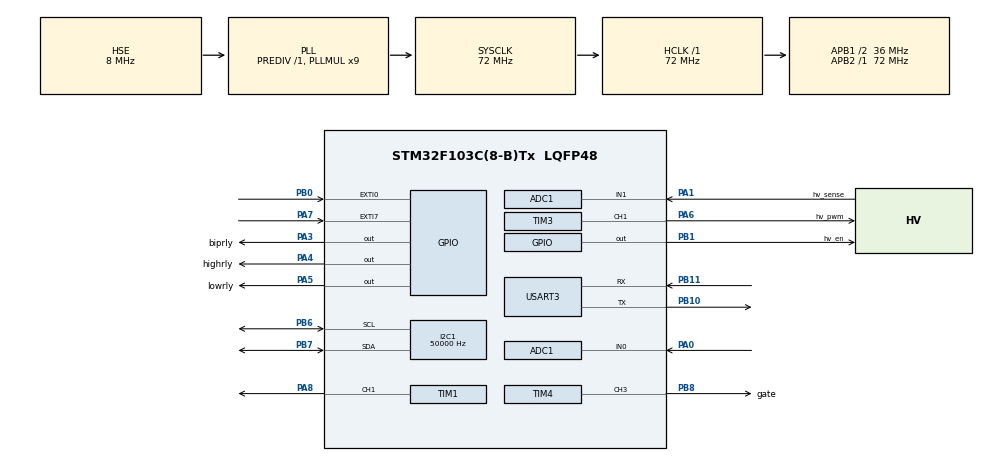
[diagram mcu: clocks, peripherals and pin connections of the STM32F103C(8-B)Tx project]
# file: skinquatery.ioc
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ADC1.Channel-3\#ChannelRegularConversion=ADC_CHANNEL_1
ADC1.Channel-4\#ChannelRegularConversion=ADC_CHANNEL_0
ADC1.ContinuousConvMode=ENABLE
ADC1.NbrOfConversion=2
ADC1.NbrOfConversionFlag=1
ADC1.Rank-3\#ChannelRegularConversion=1
ADC1.Rank-4\#ChannelRegularConversion=2
ADC1.SamplingTime-3\#ChannelRegularConversion=ADC_SAMPLETIME_28CYCLES_5
ADC1.SamplingTime-4\#ChannelRegularConversion=ADC_SAMPLETIME_28CYCLES_5
ADC1.master=1
Dma.ADC1.0.Direction=DMA_PERIPH_TO_MEMORY
Dma.ADC1.0.Instance=DMA1_Channel1
Dma.ADC1.0.MemDataAlignment=DMA_MDATAALIGN_HALFWORD
Dma.ADC1.0.MemInc=DMA_MINC_ENABLE
Dma.ADC1.0.Mode=DMA_CIRCULAR
Dma.ADC1.0.PeriphDataAlignment=DMA_PDATAALIGN_HALFWORD
Dma.ADC1.0.PeriphInc=DMA_PINC_DISABLE
Dma.ADC1.0.Priority=DMA_PRIORITY_LOW
Dma.Request0=ADC1
I2C1.ClockSpeed=50000
Mcu.Family=STM32F1
Mcu.Name=STM32F103C(8-B)Tx
Mcu.Package=LQFP48
NVIC.DMA1_Channel1_IRQn=true\:0\:0\:false\:false\:true\:false\:true\:true
NVIC.EXTI0_IRQn=true\:0\:0\:false\:false\:true\:true\:true\:true
NVIC.EXTI9_5_IRQn=true\:0\:0\:false\:false\:true\:true\:true\:true
NVIC.PriorityGroup=NVIC_PRIORITYGROUP_4
NVIC.USART3_IRQn=true\:0\:0\:false\:false\:true\:true\:true\:true
PA0-WKUP.Signal=ADCx_IN0
PA1.GPIO_Label=hv_sense
PA1.Signal=ADCx_IN1
PA13.Mode=Serial_Wire
PA13.Signal=SYS_JTMS-SWDIO
PA14.Mode=Serial_Wire
PA14.Signal=SYS_JTCK-SWCLK
PA3.GPIO_Label=biprly
PA3.Signal=GPIO_Output
PA4.GPIO_Label=highrly
PA4.Signal=GPIO_Output
PA5.GPIO_Label=lowrly
PA5.Signal=GPIO_Output
PA6.GPIO_Label=hv_pwm
PA6.Signal=S_TIM3_CH1
PA7.GPIO_ModeDefaultEXTI=GPIO_MODE_IT_RISING_FALLING
PA7.Signal=GPXTI7
PA8.Signal=S_TIM1_CH1
PB0.GPIO_ModeDefaultEXTI=GPIO_MODE_IT_RISING_FALLING
PB0.Signal=GPXTI0
PB1.GPIO_Label=hv_en
PB1.Signal=GPIO_Output
PB10.Mode=Asynchronous
PB10.Signal=USART3_TX
PB11.Mode=Asynchronous
PB11.Signal=USART3_RX
PB6.Mode=I2C
PB6.Signal=I2C1_SCL
PB7.Mode=I2C
PB7.Signal=I2C1_SDA
PB8.GPIO_Label=gate
PB8.Signal=S_TIM4_CH3
PD0-OSC_IN.Mode=HSE-External-Oscillator
PD0-OSC_IN.Signal=RCC_OSC_IN
PD1-OSC_OUT.Mode=HSE-External-Oscillator
PD1-OSC_OUT.Signal=RCC_OSC_OUT
ProjectManager.HeapSize=0x200
ProjectManager.StackSize=0x400
ProjectManager.TargetToolchain=STM32CubeIDE
RCC.ADCPresc=RCC_ADCPCLK2_DIV6
RCC.AHBFreq_Value=72000000
RCC.APB1CLKDivider=RCC_HCLK_DIV2
RCC.APB1Freq_Value=36000000
RCC.APB1TimFreq_Value=72000000
RCC.APB2Freq_Value=72000000
RCC.APB2TimFreq_Value=72000000
RCC.HCLKFreq_Value=72000000
RCC.PLLMUL=RCC_PLL_MUL9
RCC.PLLSourceVirtual=RCC_PLLSOURCE_HSE
RCC.SYSCLKFreq_VALUE=72000000
RCC.SYSCLKSource=RCC_SYSCLKSOURCE_PLLCLK
RCC.USBFreq_Value=72000000
SH.ADCx_IN0.0=ADC1_IN0,IN0
SH.ADCx_IN1.0=ADC1_IN1,IN1
SH.S_TIM1_CH1.0=TIM1_CH1,PWM Generation1 CH1
SH.S_TIM3_CH1.0=TIM3_CH1,PWM Generation1 CH1
SH.S_TIM4_CH3.0=TIM4_CH3,PWM Generation3 CH3
TIM1.Channel-PWM\ Generation1\ CH1=TIM_CHANNEL_1
TIM1.Period=999
TIM1.Prescaler=44
TIM3.AutoReloadPreload=TIM_AUTORELOAD_PRELOAD_ENABLE
TIM3.Channel-PWM\ Generation1\ CH1=TIM_CHANNEL_1
TIM3.Period=999
TIM3.Prescaler=2
TIM3.Pulse-PWM\ Generation1\ CH1=0
TIM4.AutoReloadPreload=TIM_AUTORELOAD_PRELOAD_ENABLE
TIM4.Channel-PWM\ Generation3\ CH3=TIM_CHANNEL_3
TIM4.Period=2999
TIM4.Pulse-PWM\ Generation3\ CH3=1500
USART3.VirtualMode=VM_ASYNC
board=custom

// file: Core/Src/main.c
/* USER CODE BEGIN Header */
/**
 ******************************************************************************
 * @file           : main.c
 * @brief          : Main program body
 ******************************************************************************
 * @attention
 *
 * Copyright (c) 2025 STMicroelectronics.
 * All rights reserved.
 *
 * This software is licensed under terms that can be found in the LICENSE file
 * in the root directory of this software component.
 * If no LICENSE file comes with this software, it is provided AS-IS.
 *
 ******************************************************************************
 */
/* USER CODE END Header */
#include "main.h"

/* USER CODE BEGIN Includes */
#include <stdbool.h>
#include <string.h>   // For memset()

/* USER CODE END Includes */

/* USER CODE BEGIN PD */
#define TIM3_ARR 2999
#define INPUT_MIN_HIBI  0x00
#define INPUT_MAX_HIBI 0x23
#define INPUT_MIN_LOW  0x00
#define INPUT_MAX_LOW  0xc8
#define DEBOUNCE_MS 20
#define HIGH_THRESHOLD_CH0 1.7f
#define LOW_THRESHOLD_CH0  0.0f
#define HIGH_THRESHOLD_CH1 3.2f
#define LOW_THRESHOLD_CH1  0.0f

#define ADC_MAX_VALUE   4095.0f
#define VDDA_VOLTAGE    3.3f
#define VP_LOW_VALUE         0x1000  // DWIN variable address for low value
#define VP_LOW_DATA          0x3002  // DWIN variable address for low numeric display
#define VP_VAR_ICON          0x2000  // DWIN variable address for variable icon
#define VP_MODE              0x3000  // DWIN variable address for mode (was wrongly 0x2000)
#define VP_MODE_DATA         0x3003  // DWIN page-1 value (high/bipolar only)
#define EEPROM_ADDR_MODE     0x000A  // EEPROM storage for mode (0x4d/0x4e/0x4f)
#define EEPROM_MODE_MAGIC    0xA5
#define EEPROM_ADDR_HIGH     0x0014  // EEPROM storage for high value (separate)
#define EEPROM_ADDR_BIPOLAR  0x0018  // EEPROM storage for bipolar value (separate)
#define EEPROM_ADDR_LOW      0x002A  // EEPROM storage for VP 0x1000 low value
#define EEPROM_ADDR_PAGE     0x002E  // EEPROM storage for last DWIN page (1 or 2)
#define EEPROM_PAGE_MAGIC    0xA5    // Valid page record marker byte
#define EEPROM_ADDR_PAGE_OLD 0x0200  // Legacy page address (migration read)
#define EEPROM_ADDR_VAR_ICON 0x0030  // EEPROM storage for VP 0x2000 var icon
#define EEPROM_ADDR_VAR_ICON_OLD 0x0300  // Legacy icon address (migration read)
#define EEPROM_ICON_MAGIC    0xA5    // Valid icon record marker byte
#define LOW_VALUE_MAX        200     // Maximum low value (INPUT_MAX_LOW)
#define BOOT_VAR_ICON_VALUE  78      // Default icon (low mode)
#define MIN_VAR_ICON_VALUE   77      // Bipolar icon
#define VAR_ICON_KEY_MAX     79      // High icon
#define ICON_BIPOLAR         77      // Return key 0x004D
#define ICON_LOW             78      // Return key 0x004E
#define ICON_HIGH            79      // Return key 0x004F
#define MODE_KEY_HIGH        0x004F  // VP 0x2000 return key — high mode
#define MODE_KEY_LOW         0x004E  // VP 0x2000 return key — low mode
#define MODE_KEY_BIPOLAR     0x004D  // VP 0x2000 return key — bipolar mode
#define DEFAULT_BRIGHTNESS   100     // Boot default if EEPROM empty (0-100)
#define MIN_BRIGHTNESS       30      // VP 0x0082 minimum — never go below this
#define VP_BRIGHTNESS        0x0082  // DWIN backlight variable
#define PAGE_BIPOLAR_RUN     4U      // Footswitch page — VP 0x3003 bipolar
#define PAGE_HIGH_RUN        5U      // Footswitch page — VP 0x3003 high
#define PAGE_LOW_RUN         6U      // Footswitch page — VP 0x3002 low
#define PAGE_HIBI_SET        1U      // Settings page — high / bipolar
#define PAGE_LOW_SET         2U      // Settings page — low
/* USER CODE END PD */

ADC_HandleTypeDef hadc1;
DMA_HandleTypeDef hdma_adc1;

I2C_HandleTypeDef hi2c1;

TIM_HandleTypeDef htim1;
TIM_HandleTypeDef htim3;
TIM_HandleTypeDef htim4;

UART_HandleTypeDef huart3;

/* USER CODE BEGIN PV */
#define DWIN_PKT_MAX         20
#define DWIN_RX_Q_DEPTH      8

int count;
int test;
uint8_t RxData[DWIN_PKT_MAX];
uint8_t rxBuffer[12];
uint8_t rxData[DWIN_PKT_MAX];
volatile uint16_t rxIndex = 0;
static uint8_t uart_rx_started = 0;
static volatile uint32_t last_rx_tick = 0;   /* set on every received byte */

typedef struct {
    uint8_t len;
    uint8_t data[DWIN_PKT_MAX];
} dwin_rx_pkt_t;

static volatile dwin_rx_pkt_t dwin_rx_q[DWIN_RX_Q_DEPTH];
static volatile uint8_t dwin_q_w = 0;
static volatile uint8_t dwin_q_r = 0;
uint16_t address, dataa, mode, high, bipolar, low, icon_id, brightnes,
		current_page, previous_mode;
uint8_t duty;
bool number_eeprome_flag = false;
bool sett_pg_chg = false;
bool eeprom_err = false;
uint32_t err = 0;
bool ch_pg_flag = false;
uint8_t TxData[8] = { 0x5A, 0xA5, 0x05, 0x82, 0x50, 0x02, 0x00, 0x0a };
uint8_t data[2], modee[2], highh[2], bipolarr[2], loww[2], vp3003w[2], icon_array[2],
		brightness[2], current_page_array[2];
uint16_t vp3003_val = 0;
uint16_t prev_address;
uint16_t prev_dataa;
uint16_t previous_low = 0;
uint16_t previous_high = 0;
uint16_t previous_bipolar = 0;
volatile uint8_t dwin_pkt_ready = 0;
static uint32_t low_save_enable_tick = 0;
static uint32_t low_display_push_until = 0;
static uint32_t var_icon_display_push_until = 0;
static uint32_t var_icon_boot_push_until = 0;
static uint32_t var_icon_aggressive_until = 0;
static uint32_t var_icon_save_enable_tick = 0;
static uint32_t brightness_display_push_until = 0;
static uint32_t brightness_save_enable_tick = 0;
static uint8_t brightness_user_touched = 0;
static uint8_t low_user_touched = 0;
static uint32_t low_last_accept_tick = 0;
static uint32_t low_eeprom_save_deadline = 0;
static uint8_t low_eeprom_dirty = 0;
static uint8_t low_display_pending = 0;
static uint32_t high_eeprom_save_deadline = 0;
static uint8_t high_eeprom_dirty = 0;
static uint32_t bipolar_eeprom_save_deadline = 0;
static uint8_t bipolar_eeprom_dirty = 0;
static uint8_t vp3003_display_pending = 0;
static uint32_t low_hold_last_rx_ms = 0;
static uint8_t low_hold_stream = 0;
static uint32_t low_hold_step_ms = 0;
static uint32_t low_vp1000_refresh_until = 0;
static uint16_t low_last_tx_word = 0xFFFF;
#define LOW_UART_QUIET_MS    1000U
#define LOW_RX_RAW_MAX       0x0999U  /* allow BCD 12.0 = 0x0120 from DWIN */

/* ===== TEMP DIAGNOSTIC =====
 * When set to 1, every VP 0x1000 value the DWIN sends is echoed *raw* (no
 * conversion) onto VP 0x3002. This lets us read on-screen exactly what the
 * DWIN transmits for a given key press. Set back to 0 once captured. */
#define LOW_DIAG_RAW   0

/* VP 0x1000 is the low increment on page 2 (and can appear on run pages). */
static uint8_t dwin_page_is_low(void) {
    return (current_page == PAGE_HIBI_SET || current_page == PAGE_LOW_SET ||
            current_page == PAGE_BIPOLAR_RUN || current_page == PAGE_LOW_RUN);
}

static uint8_t dwin_tx_low_quiet(void) {
    if (mode != 0x4e || !low_user_touched) {
        return 0U;
    }
    if (!dwin_page_is_low()) {
        return 0U;
    }
    return ((HAL_GetTick() - low_last_accept_tick) < LOW_UART_QUIET_MS) ? 1U : 0U;
}

static uint32_t vp3003_last_accept_tick = 0;
#define VP3003_UART_QUIET_MS  800U

static uint8_t dwin_tx_page1_quiet(void) {
    if (current_page != 1U) {
        return 0U;
    }
    if (mode != 0x4f && mode != 0x4d) {
        return 0U;
    }
    if (vp3003_last_accept_tick == 0U) {
        return 0U;
    }
    return ((HAL_GetTick() - vp3003_last_accept_tick) < VP3003_UART_QUIET_MS) ? 1U : 0U;
}

static uint8_t dwin_tx_user_adjust_quiet(void) {
    return (dwin_tx_low_quiet() || dwin_tx_page1_quiet()) ? 1U : 0U;
}
static uint32_t vp3003_save_enable_tick = 0;
static uint32_t vp3003_page1_restore_until = 0;
static uint8_t vp3003_user_touched = 0;
static uint32_t vp3003_rx_ignore_until = 0;
static uint32_t boot_rx_lock_until = 0;
static uint8_t saved_settings_page = 0;
static uint8_t var_icon_user_locked = 0;
static uint32_t boot_page_guard_until = 0;
uint32_t delta = 0;
float frequency = 0.0;
volatile uint8_t footswitch = 0;
volatile uint8_t active = 0;
volatile uint32_t pa7_last_irq = 0;
volatile uint8_t pa7_pending = 0;
volatile uint32_t pb0_last_irq = 0;
volatile uint8_t pb0_pending = 0;
uint8_t pagechange[10] = { 0x5A, 0xA5, 0x07, 0x82, 0x00, 0x84, 0x5A, 0x01, 0x00, 0x01 };
uint8_t mapped_duty = 0;

uint16_t adc_dma_buf[2];
uint16_t adc_raw_ch1;
uint16_t adc_raw_ch0;
uint32_t last_adc_tick = 0;
uint8_t alert_hv = 0;
uint8_t alert_gate = 0;

float ch1_voltage;
float ch0_voltage=1.6f;

// Variable icon storage (VP 0x2000)
uint16_t var_icon_value = BOOT_VAR_ICON_VALUE;
uint8_t var_icon_data[2] = {0x00, 0x4E};  // 78 = 0x004E low icon
/* USER CODE END PV */

void SystemClock_Config(void);
static void MX_GPIO_Init(void);
static void MX_DMA_Init(void);
static void MX_ADC1_Init(void);
static void MX_TIM3_Init(void);
static void MX_TIM4_Init(void);
static void MX_I2C1_Init(void);
static void MX_USART3_UART_Init(void);
static void MX_TIM1_Init(void);
/* USER CODE BEGIN PFP */
void bi_hi_pwm(uint16_t dataa);
void lowfunction(uint16_t dataa);
void TIM3_SetDutyPercent(uint8_t duty);
void save_reading(void);
void send_loadings(void);
void debouncing(void);
void hv_adc_reading(void);
void send_low_to_display(void);
void send_page_change(uint8_t page_num);
void dwin_boot_to_page(uint8_t page_num);
void dwin_uart_rx_start(void);
void low_value_user_changed(uint16_t new_low, uint16_t src_addr);
void send_variable_data(uint8_t addr_high, uint8_t addr_low, uint8_t data_high, uint8_t data_low);
void dwin_set_var_icon(uint16_t icon_id);
void send_var_icon_to_display(void);
void dwin_apply_boot_var_icon(void);
void eeprom_read_low_value(void);
void eeprom_save_low_value(void);
void eeprom_read_brightness(void);
void dwin_send_brightness(void);
void dwin_refresh_brightness(void);
void low_sync_both_vps(void);
void low_push_display_from_eeprom(void);
void eeprom_read_vp3003_value(void);
void eeprom_read_var_icon(void);
void eeprom_save_var_icon(void);
void eeprom_save_current_page(uint8_t page_num);
static void dwin_restore_page_from_eeprom(uint8_t page_num);
static void dwin_show_settings_page(uint8_t page_num);
static void dwin_arm_page2_restore_timers(void);
static void dwin_arm_var_icon_timers(void);
static void dwin_restore_var_icon_from_eeprom(uint8_t burst_count);
static void dwin_push_icon_from_eeprom(void);
static void dwin_icon_burst_from_eeprom(uint8_t count);
static uint8_t var_icon_from_mode_key(uint16_t key);
static uint8_t var_icon_from_mode(uint16_t m);
static void var_icon_apply_return_key(uint16_t key);
static uint8_t dwin_get_boot_page(void);
void dwin_restore_saved_state(uint8_t page_num);
void vp3003_send_to_display(void);
static void vp3003_send_to_display_force(void);
static void vp3003_push_display_burst(uint8_t count);
static void vp3003_bind_active(void);
static void vp3003_hold_service(void);
static void eeprom_save_hibi_slot(uint16_t which_mode);
static void hibi_persist_now(uint16_t which_mode);
static void eeprom_read_hibi_slot(uint16_t which_mode);
static void eeprom_save_mode_now(void);
static void eeprom_persist_all_values(void);
static void eeprom_persist_leaving_state(uint16_t old_mode);
static void dwin_picset_force(uint8_t page_num);
static void dwin_after_page_values(uint8_t page_num);
static uint16_t mode_normalize(uint16_t raw);
void vp3003_user_changed(uint16_t new_val);
void dwin_refresh_page2_values(void);
void dwin_open_page2(void);
void dwin_refresh_page1_values(void);
void dwin_open_page1(void);
/* USER CODE END PFP */

/* USER CODE BEGIN 0 */
static uint8_t i2c_eeprom_read16(uint16_t addr, uint8_t *buf);
static void dwin_uart_send(const uint8_t *data, uint16_t len);
static void send_var_icon_fast(void);
static void dwin_icon_burst_fast(uint8_t count);
static void send_variable_data_fast(uint8_t ah, uint8_t al, uint8_t dh, uint8_t dl);
static void low_apply_value(uint16_t val);
static void low_push_vps_fast(void);
static void low_burst_vp3002(uint8_t n);
static void low_persist_now(void);
static void low_hold_service(void);
static void low_vp1000_rx(uint16_t rx_val);

/* VP 0x1000 is a DGUS Variable Icon: the value it holds is an ICON INDEX.
 *   icon 0..99    -> 0.0 .. 9.9   (tenths = icon)
 *   icon 100..110 -> 10   .. 20   (tenths = (icon - 90) * 10)
 * Internally `low` is kept in tenths (0..200). VP 0x3002 is a 1-decimal
 * numeric box, so it takes tenths directly. */
static uint16_t low_icon_to_tenths(uint16_t icon) {
    if (icon <= 99U) {
        return icon;
    }
    if (icon <= 110U) {
        return (uint16_t)((icon - 90U) * 10U);
    }
    return LOW_VALUE_MAX;   /* 200 = 20.0 */
}

static uint16_t low_tenths_to_icon(uint16_t tenths) {
    if (tenths > LOW_VALUE_MAX) {
        tenths = LOW_VALUE_MAX;
    }
    if (tenths <= 99U) {
        return tenths;                       /* 0.0-9.9 -> icon 0-99 */
    }
    return (uint16_t)((tenths / 10U) + 90U); /* 10.0-20.0 -> icon 100-110 */
}

static uint16_t low_rx_to_tenths(uint16_t val) {
    return low_icon_to_tenths(val);
}

static uint16_t low_display_word(void) {
    uint16_t v = (previous_low != 0U && low == 0U) ? previous_low : low;
    if (v > LOW_VALUE_MAX) {
        v = LOW_VALUE_MAX;
    }
    return v;
}

static void low_push_vp3002_only(void) {
    /* VP 0x3002 is a 1-decimal Data Variable display: send the value in tenths
     * (e.g. 18.0 -> 180). VP 0x1000 (Variable Icon) gets the icon index instead. */
    uint16_t tenths = low_display_word();
    uint8_t d2h = (uint8_t)((tenths >> 8) & 0xFF);
    uint8_t d2l = (uint8_t)(tenths & 0xFF);
    uint8_t cmd[8] = {0x5A, 0xA5, 0x05, 0x82,
                      (uint8_t)((VP_LOW_DATA >> 8) & 0xFF),
                      (uint8_t)(VP_LOW_DATA & 0xFF), d2h, d2l};
    dwin_uart_send(cmd, 8);
    low_last_tx_word = tenths;
}

/* VP 0x1000: only rewrite 0.0–9.9. For 10–20 leave DWIN's value (writing tenths blanks it). */
static void low_push_vp1000_only(void) {
    uint16_t tenths;
    uint16_t icon;
    uint8_t cmd[8];
    if (dwin_tx_low_quiet()) {
        return;
    }
    tenths = low_display_word();
    icon = low_tenths_to_icon(tenths);   /* VP 0x1000 is a Variable Icon: send icon index */
    cmd[0] = 0x5A; cmd[1] = 0xA5; cmd[2] = 0x05; cmd[3] = 0x82;
    cmd[4] = (uint8_t)((VP_LOW_VALUE >> 8) & 0xFF);
    cmd[5] = (uint8_t)(VP_LOW_VALUE & 0xFF);
    cmd[6] = (uint8_t)((icon >> 8) & 0xFF);
    cmd[7] = (uint8_t)(icon & 0xFF);
    dwin_uart_send(cmd, 8);
    low_last_tx_word = tenths;
}

static void low_arm_page2_vp1000(void) {
    low_vp1000_refresh_until = HAL_GetTick() + 4000U;
}

static void low_burst_vp3002(uint8_t n) {
    uint8_t i;
    for (i = 0U; i < n; i++) {
        low_push_vp3002_only();
        HAL_Delay(8);
    }
}

/* After PICSET, paint the same low word on VP 0x1000 and VP 0x3002. */
static void low_burst_vp1000(uint8_t n) {
    uint8_t i;
    for (i = 0U; i < n; i++) {
        low_push_vp1000_only();
        low_push_vp3002_only();
        HAL_Delay(8);
    }
    low_arm_page2_vp1000();
}

static uint16_t mode_normalize(uint16_t raw) {
    if (raw == 0x4dU || raw == 0x4eU || raw == 0x4fU) {
        return raw;
    }
    raw &= 0x00FFU;
    if (raw == 0x4dU || raw == 0x4eU || raw == 0x4fU) {
        return raw;
    }
    return 0U;
}

static uint16_t mode_from_icon(uint16_t icon) {
    if (icon == ICON_HIGH) {
        return 0x4fU;
    }
    if (icon == ICON_LOW) {
        return 0x4eU;
    }
    if (icon == ICON_BIPOLAR) {
        return 0x4dU;
    }
    return 0U;
}

static uint16_t hibi_clamp(uint16_t raw) {
    if (raw == 0xFFFFU) {
        return 0U;
    }
    if (raw > INPUT_MAX_HIBI) {
        return INPUT_MAX_HIBI;
    }
    return raw;
}

static void dwin_picset_force(uint8_t page_num) {
    uint8_t cmd[10] = {
        0x5A, 0xA5, 0x07, 0x82, 0x00, 0x84,
        0x5A, 0x01, 0x00, page_num
    };
    dwin_uart_send(cmd, 10);
    current_page = page_num;
}

static void dwin_rx_queue_push(const uint8_t *pkt, uint8_t len) {
    uint8_t next = (uint8_t)((dwin_q_w + 1U) % DWIN_RX_Q_DEPTH);
    if (next == dwin_q_r) {
        dwin_q_r = (uint8_t)((dwin_q_r + 1U) % DWIN_RX_Q_DEPTH);
    }
    if (len > DWIN_PKT_MAX) {
        len = DWIN_PKT_MAX;
    }
    memcpy((void *)dwin_rx_q[dwin_q_w].data, pkt, len);
    dwin_rx_q[dwin_q_w].len = len;
    dwin_q_w = next;
}

static uint8_t dwin_rx_queue_pop(uint8_t *pkt, uint8_t max_len) {
    if (dwin_q_r == dwin_q_w) {
        return 0U;
    }
    uint8_t len = dwin_rx_q[dwin_q_r].len;
    if (len > max_len) {
        len = max_len;
    }
    memcpy(pkt, (const void *)dwin_rx_q[dwin_q_r].data, len);
    dwin_q_r = (uint8_t)((dwin_q_r + 1U) % DWIN_RX_Q_DEPTH);
    return len;
}

static void dwin_rx_collect_packets(void) {
    while (rxIndex >= 5U) {
        if (rxData[0] != 0x5A || rxData[1] != 0xA5) {
            memmove(rxData, rxData + 1, rxIndex - 1U);
            rxIndex--;
            continue;
        }
        uint8_t total_len = (uint8_t)(rxData[2] + 3U);
        if (total_len < 4U || total_len > DWIN_PKT_MAX) {
            memmove(rxData, rxData + 1, rxIndex - 1U);
            rxIndex--;
            continue;
        }
        if (rxIndex < total_len) {
            break;
        }
        dwin_rx_queue_push(rxData, total_len);
        if (rxIndex > total_len) {
            memmove(rxData, rxData + total_len, rxIndex - total_len);
            rxIndex = (uint16_t)(rxIndex - total_len);
        } else {
            rxIndex = 0;
        }
    }
}

void HAL_UART_RxCpltCallback(UART_HandleTypeDef *huart) {
	if (huart->Instance == USART3) {
		last_rx_tick = HAL_GetTick();
		if (rxIndex < sizeof(rxData)) {
			rxData[rxIndex++] = rxBuffer[0];
		}

		HAL_UART_Receive_IT(&huart3, rxBuffer, 1);
		dwin_rx_collect_packets();
	}
}

void HAL_GPIO_EXTI_Callback(uint16_t GPIO_Pin) {
	if (GPIO_Pin == GPIO_PIN_7) {
		pa7_last_irq = HAL_GetTick();
		pa7_pending = 1;
	}

	if (GPIO_Pin == GPIO_PIN_0) {
		pb0_last_irq = HAL_GetTick();
		pb0_pending = 1;
	}
}

void dwin_uart_rx_start(void) {
    if (!uart_rx_started) {
        rxIndex = 0;
        memset(rxData, 0, sizeof(rxData));
        HAL_UART_Receive_IT(&huart3, rxBuffer, 1);
        uart_rx_started = 1;
        boot_rx_lock_until = HAL_GetTick() + 3000U;
    }
}

void dwin_rx_get_vp(uint16_t *addr, uint16_t *data, uint8_t *valid) {
    *valid = 0;
    if (RxData[0] != 0x5A || RxData[1] != 0xA5 || RxData[2] < 3) {
        return;
    }

    *addr = (uint16_t)(((uint16_t)RxData[4] << 8) | RxData[5]);
    uint16_t max_val = LOW_VALUE_MAX;
    if (*addr == VP_MODE_DATA) {
        if (mode == 0x4f || mode == 0x4d) {
            max_val = INPUT_MAX_HIBI;
        }
    } else if (*addr == VP_VAR_ICON) {
        max_val = VAR_ICON_KEY_MAX;
    } else if (*addr == VP_BRIGHTNESS) {
        max_val = 100;
    }

    uint8_t cmd = RxData[3];
    uint8_t len = RxData[2];

    /* Return keys 0x004D / 0x004E / 0x004F must parse even if byte order varies. */
    if (*addr == VP_VAR_ICON) {
        uint16_t cand[4] = {0, 0, 0, 0};
        uint8_t n = 0U;
        if (cmd == 0x83 && len >= 6) {
            cand[n++] = (uint16_t)(((uint16_t)RxData[7] << 8) | RxData[8]);
            cand[n++] = (uint16_t)(((uint16_t)RxData[8] << 8) | RxData[7]);
        }
        if (len >= 5) {
            cand[n++] = (uint16_t)(((uint16_t)RxData[6] << 8) | RxData[7]);
            cand[n++] = (uint16_t)(((uint16_t)RxData[7] << 8) | RxData[6]);
        }
        {
            uint8_t i;
            for (i = 0U; i < n; i++) {
                uint16_t v = cand[i];
                if (v == 0x004DU || v == 0x004EU || v == 0x004FU ||
                    v == 0x4dU || v == 0x4eU || v == 0x4fU) {
                    *data = v;
                    *valid = 1;
                    return;
                }
            }
        }
    }

    if (*addr == VP_BRIGHTNESS && cmd == 0x83) {
        if (len >= 6) {
            uint16_t v = (uint16_t)(((uint16_t)RxData[7] << 8) | RxData[8]);
            if (v <= 100U) {
                *data = v;
                *valid = 1;
            } else if (RxData[7] <= 100U) {
                *data = RxData[7];
                *valid = 1;
            } else if (RxData[8] <= 100U) {
                *data = RxData[8];
                *valid = 1;
            }
            return;
        }
        if (len >= 4) {
            uint16_t be = (uint16_t)(((uint16_t)RxData[6] << 8) | RxData[7]);
            uint16_t le = (uint16_t)(((uint16_t)RxData[7] << 8) | RxData[6]);
            if (be <= 100U) {
                *data = be;
                *valid = 1;
            } else if (le <= 100U) {
                *data = le;
                *valid = 1;
            } else if (RxData[7] <= 100U) {
                *data = RxData[7];
                *valid = 1;
            }
            return;
        }
    }

    /* DWIN brightness write is often 5A A5 04 82 00 82 VV (len=4, one data byte) */
    if (*addr == VP_BRIGHTNESS && cmd == 0x82) {
        if (len >= 4 && RxData[6] <= 100U) {
            *data = RxData[6];
            *valid = 1;
            return;
        }
        if (len >= 5) {
            uint16_t be = (uint16_t)(((uint16_t)RxData[6] << 8) | RxData[7]);
            uint16_t le = (uint16_t)(((uint16_t)RxData[7] << 8) | RxData[6]);
            if (be <= 100U) {
                *data = be;
                *valid = 1;
            } else if (le <= 100U) {
                *data = le;
                *valid = 1;
            }
            return;
        }
    }

    if ((*addr == VP_LOW_VALUE || *addr == VP_LOW_DATA) && cmd == 0x83) {
        if (len >= 6) {
            uint16_t v78 = (uint16_t)(((uint16_t)RxData[7] << 8) | RxData[8]);
            uint16_t v67 = (uint16_t)(((uint16_t)RxData[6] << 8) | RxData[7]);
            if (v78 <= LOW_RX_RAW_MAX) {
                *data = v78;
                *valid = 1;
            } else if (v67 <= LOW_RX_RAW_MAX) {
                *data = v67;
                *valid = 1;
            }
            return;
        }
        if (len >= 5) {
            uint16_t be = (uint16_t)(((uint16_t)RxData[6] << 8) | RxData[7]);
            uint16_t le = (uint16_t)(((uint16_t)RxData[7] << 8) | RxData[6]);
            if (be <= LOW_RX_RAW_MAX) {
                *data = be;
                *valid = 1;
            } else if (le <= LOW_RX_RAW_MAX) {
                *data = le;
                *valid = 1;
            }
            return;
        }
        if (len >= 4 && RxData[6] <= LOW_VALUE_MAX) {
            *data = RxData[6];
            *valid = 1;
            return;
        }
    }

    if ((*addr == VP_LOW_VALUE || *addr == VP_LOW_DATA) && cmd == 0x82) {
        /* Prefer 2-byte value before single byte (00 01 must be 1, not 0) */
        if (len >= 5) {
            uint16_t be = (uint16_t)(((uint16_t)RxData[6] << 8) | RxData[7]);
            uint16_t le = (uint16_t)(((uint16_t)RxData[7] << 8) | RxData[6]);
            if (be <= LOW_RX_RAW_MAX) {
                *data = be;
                *valid = 1;
                return;
            }
            if (le <= LOW_RX_RAW_MAX) {
                *data = le;
                *valid = 1;
                return;
            }
        }
        if (len >= 4 && RxData[6] <= LOW_VALUE_MAX) {
            *data = RxData[6];
            *valid = 1;
        }
        return;
    }

    if (cmd == 0x82 && len >= 5) {
        uint16_t be = (uint16_t)(((uint16_t)RxData[6] << 8) | RxData[7]);
        uint16_t le = (uint16_t)(((uint16_t)RxData[7] << 8) | RxData[6]);
        /* Shared +/- on VP 0x3003: accept user increment (1–35). Ignore 0 (page default). */
        if (*addr == VP_MODE_DATA) {
            if (be >= 1U && be <= INPUT_MAX_HIBI) {
                *data = be;
                *valid = 1;
            } else if (le >= 1U && le <= INPUT_MAX_HIBI) {
                *data = le;
                *valid = 1;
            }
            return;
        }
        if (be <= max_val) {
            *data = be;
            *valid = 1;
        } else if (le <= max_val) {
            *data = le;
            *valid = 1;
        }
        return;
    }

    if (cmd == 0x83) {
        uint16_t c1 = 0, c2 = 0, c3 = 0;
        if (*addr == VP_MODE_DATA) {
            max_val = INPUT_MAX_HIBI;
        }
        if (len >= 6) {
            c1 = (uint16_t)(((uint16_t)RxData[7] << 8) | RxData[8]);
            c2 = (uint16_t)(((uint16_t)RxData[8] << 8) | RxData[7]);
            c3 = (uint16_t)(((uint16_t)RxData[6] << 8) | RxData[7]);
        } else if (len >= 4) {
            c1 = (uint16_t)(((uint16_t)RxData[6] << 8) | RxData[7]);
            c2 = (uint16_t)(((uint16_t)RxData[7] << 8) | RxData[6]);
        }
        if (c1 <= max_val) {
            *data = c1;
            *valid = 1;
        } else if (c2 <= max_val) {
            *data = c2;
            *valid = 1;
        } else if (c3 <= max_val) {
            *data = c3;
            *valid = 1;
        }
    }
}

static void low_sync_display_vp(void) {
    low_push_vps_fast();
}

/* During user +/- hold: listen only — push VP 0x3002/0x1000 after adjust stops */
static void send_variable_data_fast(uint8_t addr_high, uint8_t addr_low,
                                    uint8_t data_high, uint8_t data_low) {
    uint16_t vp = (uint16_t)(((uint16_t)addr_high << 8) | addr_low);
    if (dwin_tx_low_quiet() && vp == VP_LOW_VALUE) {
        return;
    }
    if (dwin_tx_page1_quiet() && vp == VP_MODE_DATA) {
        return;
    }
    uint8_t cmd[8] = {
        0x5A, 0xA5, 0x05, 0x82,
        addr_high, addr_low, data_high, data_low
    };
    dwin_uart_send(cmd, 8);
}

static void low_push_vps_fast(void) {
    low_push_vp1000_only();
    low_push_vp3002_only();
}

static void low_apply_value(uint16_t val) {
    val = low_rx_to_tenths(val);
    if (val == 0U && previous_low != 0U) {
        low = previous_low;
        loww[0] = (uint8_t)((low >> 8) & 0xFF);
        loww[1] = (uint8_t)(low & 0xFF);
        return;
    }

    low_user_touched = 1;
    low_display_push_until = 0;
    var_icon_display_push_until = 0;
    var_icon_boot_push_until = 0;
    var_icon_aggressive_until = 0;
    low_last_accept_tick = HAL_GetTick();
    low_display_pending = 1;

    if (val != low) {
        low = val;
        previous_low = val;
        loww[0] = (uint8_t)((low >> 8) & 0xFF);
        loww[1] = (uint8_t)(low & 0xFF);
        low_eeprom_dirty = 1;
        low_eeprom_save_deadline = HAL_GetTick() + 150;
        low_push_vp3002_only();
        low_persist_now();
        if (mode == 0x4e && ((footswitch) || (active))) {
            lowfunction(low);
        }
    } else if (low != 0U) {
        previous_low = low;
        low_push_vp3002_only();
    }
}

/* MODIFIED: Removed save_enable_tick check for instant response */
static void low_vp1000_rx(uint16_t rx_val) {
    low_user_touched = 1;
    low_display_push_until = 0;
    var_icon_aggressive_until = 0;
    var_icon_display_push_until = 0;
    var_icon_boot_push_until = 0;
    low_last_accept_tick = HAL_GetTick();
    low_display_pending = 1;
    low_apply_value(rx_val);
}

static void low_hold_service(void) {
    static uint32_t last_show_ms;
    if (dwin_tx_low_quiet()) {
        return;
    }
    uint32_t now = HAL_GetTick();
    if (current_page == 2U) {
        uint32_t gap = (now < low_vp1000_refresh_until) ? 80U : 200U;
        if ((now - last_show_ms) >= gap) {
            low_push_vp3002_only();
            last_show_ms = now;
        }
        return;
    }
    if (current_page == 6U && mode == 0x4e && (now - last_show_ms) >= 200U) {
        low_push_vp3002_only();
        last_show_ms = now;
    }
}

void low_value_user_changed(uint16_t new_low, uint16_t src_addr) {
    (void)src_addr;
    low_apply_value(new_low);
}

static void low_persist_now(void) {
    if (low == 0U && previous_low != 0U) {
        low = previous_low;
        loww[0] = (uint8_t)((low >> 8) & 0xFF);
        loww[1] = (uint8_t)(low & 0xFF);
    }
    if (low == 0U) {
        return;
    }
    eeprom_save_low_value();
    low_eeprom_dirty = 0;
}

static void low_eeprom_flush(void) {
    if (!low_eeprom_dirty) {
        return;
    }
    if ((int32_t)(HAL_GetTick() - low_eeprom_save_deadline) < 0) {
        return;
    }
    low_persist_now();
}

static void low_display_flush(void) {
    if (!low_display_pending) {
        return;
    }
    if (dwin_tx_low_quiet()) {
        return;
    }
    low_display_pending = 0;
    low_push_vps_fast();
}

static void low_handle_rx(uint16_t new_low, uint16_t src_addr) {
    /* VP 0x3002 is display-only. Page 6 default 11.0 must not overwrite the last VP1000 value. */
    if (src_addr == VP_LOW_DATA) {
        return;
    }
    if (src_addr != VP_LOW_VALUE) {
        return;
    }
    if (HAL_GetTick() < boot_rx_lock_until) {
        return;
    }
    {
        uint16_t tenths = low_rx_to_tenths(new_low);
        /* Page-2 default 0.2 must never replace a saved low value. */
        if (tenths == 2U && !low_user_touched) {
            return;
        }
        if (HAL_GetTick() < low_save_enable_tick) {
            if (tenths == 0U || tenths == 2U) {
                return;
            }
            if (previous_low != 0U && tenths != previous_low && tenths < 10U) {
                return;
            }
        }
    }
    low_vp1000_rx(new_low);
}

/* MODIFIED: Reduced timeout for faster UART response */
static void dwin_uart_send(const uint8_t *data, uint16_t len) {
    uint8_t restart_rx = uart_rx_started;
    if (restart_rx) {
        HAL_UART_AbortReceive_IT(&huart3);
    }
    __HAL_UART_CLEAR_OREFLAG(&huart3);
    if (HAL_UART_Transmit(&huart3, (uint8_t *)data, len, 100) != HAL_OK) {
        HAL_Delay(2);
        HAL_UART_Transmit(&huart3, (uint8_t *)data, len, 100);
    }
    if (restart_rx) {
        HAL_UART_Receive_IT(&huart3, rxBuffer, 1);
    }
}

void send_page_change(uint8_t page_num) {
    if (current_page == page_num) {
        return;
    }
    dwin_picset_force(page_num);
    /* DGUS reloads page defaults on PICSET — wait, then rewrite VPs */
    HAL_Delay(80);
    dwin_after_page_values(page_num);
    if (page_num == PAGE_HIBI_SET || page_num == PAGE_LOW_SET) {
        eeprom_save_current_page(page_num);
    }
}

void dwin_boot_to_page(uint8_t page_num) {
    HAL_Delay(3000);  /* show splash (00.bmp) */

    if (low == 0U && previous_low != 0U) {
        low = previous_low;
        loww[0] = (uint8_t)((low >> 8) & 0xFF);
        loww[1] = (uint8_t)(low & 0xFF);
    }
    vp3003_bind_active();
    dwin_set_var_icon(var_icon_from_mode(mode));

    /* Leave splash once, then paint last state immediately from RAM. */
    dwin_picset_force(page_num);
    HAL_Delay(50);
    current_page = page_num;
    send_variable_data(0x30, 0x00, modee[0], modee[1]);
    send_var_icon_fast();
    dwin_after_page_values(page_num);
    /* Force low value onto the screen after PICSET defaults. */
    if (page_num == PAGE_LOW_SET || page_num == PAGE_LOW_RUN) {
        low_burst_vp1000(3);
        low_burst_vp3002(3);
    }
    low_save_enable_tick = HAL_GetTick() + 2000U;
    vp3003_save_enable_tick = HAL_GetTick() + 2000U;
    vp3003_rx_ignore_until = HAL_GetTick() + 800U;
}

void send_variable_data(uint8_t addr_high, uint8_t addr_low, uint8_t data_high, uint8_t data_low) {
    uint16_t vp = (uint16_t)(((uint16_t)addr_high << 8) | addr_low);
    if (dwin_tx_low_quiet() && vp == VP_LOW_VALUE) {
        return;
    }
    if (dwin_tx_page1_quiet() && vp == VP_MODE_DATA) {
        return;
    }
    uint8_t cmd[8] = {
        0x5A, 0xA5, 0x05, 0x82,
        addr_high, addr_low, data_high, data_low
    };
    dwin_uart_send(cmd, 8);
}

void dwin_set_var_icon(uint16_t icon_id) {
    var_icon_value = icon_id;
    var_icon_data[0] = (uint8_t)((icon_id >> 8) & 0xFF);
    var_icon_data[1] = (uint8_t)(icon_id & 0xFF);
}

void send_var_icon_to_display(void) {
    if (dwin_tx_user_adjust_quiet()) {
        return;
    }
    uint8_t cmd[8] = {
        0x5A, 0xA5, 0x05, 0x82,
        (uint8_t)((VP_VAR_ICON >> 8) & 0xFF),
        (uint8_t)(VP_VAR_ICON & 0xFF),
        var_icon_data[0], var_icon_data[1]
    };
    dwin_uart_send(cmd, 8);
    HAL_Delay(2);
}

static void send_var_icon_fast(void) {
    if (dwin_tx_user_adjust_quiet()) {
        return;
    }
    uint8_t cmd[8] = {
        0x5A, 0xA5, 0x05, 0x82,
        (uint8_t)((VP_VAR_ICON >> 8) & 0xFF),
        (uint8_t)(VP_VAR_ICON & 0xFF),
        var_icon_data[0], var_icon_data[1]
    };
    dwin_uart_send(cmd, 8);
}

void eeprom_save_current_page(uint8_t page_num) {
    if (page_num != 1U && page_num != 2U) {
        return;
    }
    saved_settings_page = page_num;
    current_page_array[0] = EEPROM_PAGE_MAGIC;
    current_page_array[1] = page_num;
    if (HAL_I2C_IsDeviceReady(&hi2c1, 0x50 << 1, 1, 10) == HAL_OK) {
        HAL_I2C_Mem_Write(&hi2c1, 0x50 << 1, EEPROM_ADDR_PAGE,
                          I2C_MEMADD_SIZE_16BIT, current_page_array, 2, 1000);
        HAL_Delay(10);
    }
}

static uint8_t eeprom_parse_saved_page(const uint8_t *buf) {
    if (buf[0] == EEPROM_PAGE_MAGIC &&
        (buf[1] == 1U || buf[1] == 2U)) {
        return buf[1];
    }
    if (buf[0] == 0x00U && (buf[1] == 1U || buf[1] == 2U)) {
        return buf[1];
    }
    return 0U;
}

static uint8_t var_icon_from_mode_key(uint16_t key) {
    if (key == MODE_KEY_HIGH || key == 0x004f || key == 0x4f) {
        return ICON_HIGH;
    }
    if (key == MODE_KEY_LOW || key == 0x004e || key == 0x4e) {
        return ICON_LOW;
    }
    if (key == MODE_KEY_BIPOLAR || key == 0x004d || key == 0x4d) {
        return ICON_BIPOLAR;
    }
    return 0U;
}

static uint8_t var_icon_from_mode(uint16_t m) {
    if (m == 0x4f) {
        return ICON_HIGH;
    }
    if (m == 0x4e) {
        return ICON_LOW;
    }
    if (m == 0x4d) {
        return ICON_BIPOLAR;
    }
    return BOOT_VAR_ICON_VALUE;
}

void eeprom_read_var_icon(void) {
    uint8_t buf[2] = {0xFF, 0xFF};
    uint8_t legacy[2] = {0xFF, 0xFF};

    dwin_set_var_icon(var_icon_from_mode(mode));

    if (i2c_eeprom_read16(EEPROM_ADDR_VAR_ICON, buf)) {
        if (buf[0] == EEPROM_ICON_MAGIC &&
            buf[1] >= MIN_VAR_ICON_VALUE && buf[1] <= VAR_ICON_KEY_MAX) {
            dwin_set_var_icon((uint16_t)buf[1]);
            return;
        }

        uint16_t icon = (uint16_t)(((uint16_t)buf[0] << 8) | buf[1]);
        if (icon >= MIN_VAR_ICON_VALUE && icon <= VAR_ICON_KEY_MAX) {
            dwin_set_var_icon(icon);
            eeprom_save_var_icon();
            return;
        }
    }

    if (i2c_eeprom_read16(EEPROM_ADDR_VAR_ICON_OLD, legacy)) {
        if (legacy[0] == EEPROM_ICON_MAGIC &&
            legacy[1] >= MIN_VAR_ICON_VALUE && legacy[1] <= VAR_ICON_KEY_MAX) {
            dwin_set_var_icon((uint16_t)legacy[1]);
            eeprom_save_var_icon();
            return;
        }

        uint16_t icon = (uint16_t)(((uint16_t)legacy[0] << 8) | legacy[1]);
        if (icon >= MIN_VAR_ICON_VALUE && icon <= VAR_ICON_KEY_MAX) {
            dwin_set_var_icon(icon);
            return;
        }
    }
}

void eeprom_save_var_icon(void) {
    uint8_t buf[2];

    if (var_icon_value < MIN_VAR_ICON_VALUE || var_icon_value > VAR_ICON_KEY_MAX) {
        return;
    }

    buf[0] = EEPROM_ICON_MAGIC;
    buf[1] = (uint8_t)var_icon_value;
    var_icon_data[0] = 0x00;
    var_icon_data[1] = buf[1];

    if (HAL_I2C_IsDeviceReady(&hi2c1, 0x50 << 1, 1, 10) == HAL_OK) {
        HAL_I2C_Mem_Write(&hi2c1, 0x50 << 1, EEPROM_ADDR_VAR_ICON,
                          I2C_MEMADD_SIZE_16BIT, buf, 2, 1000);
        HAL_Delay(10);
        if (current_page == 1U || current_page == 2U) {
            eeprom_save_current_page((uint8_t)current_page);
        }
    } else {
        eeprom_err = true;
    }
}

static uint8_t dwin_get_boot_page(void) {
    /* Boot page follows mode so VP 0x3003 (page 1) or VP 0x3002 (page 2) is visible. */
    if (mode == 0x4fU || mode == 0x4dU) {
        return 1U;
    }
    return 2U;
}

static void eeprom_read_saved_page(void) {
    uint8_t legacy[2] = {0xFF, 0xFF};
    saved_settings_page = 0;
    current_page = 0;
    current_page_array[0] = 0xFF;
    current_page_array[1] = 0xFF;

    if (i2c_eeprom_read16(EEPROM_ADDR_PAGE, current_page_array)) {
        saved_settings_page = eeprom_parse_saved_page(current_page_array);
    }

    if (saved_settings_page == 0U &&
        i2c_eeprom_read16(EEPROM_ADDR_PAGE_OLD, legacy)) {
        saved_settings_page = eeprom_parse_saved_page(legacy);
        if (saved_settings_page != 0U) {
            eeprom_save_current_page(saved_settings_page);
        }
    }

    /* Leave current_page at 0: the DWIN is still on splash until
       dwin_boot_to_page() sends PICSET. */
}

void eeprom_read_low_value(void) {
    uint8_t buf[2];

    if (HAL_I2C_IsDeviceReady(&hi2c1, 0x50 << 1, 3, 50) != HAL_OK) {
        return;
    }

    if (HAL_I2C_Mem_Read(&hi2c1, 0x50 << 1, EEPROM_ADDR_LOW, I2C_MEMADD_SIZE_16BIT,
                         buf, 2, 1000) != HAL_OK) {
        return;
    }
    HAL_Delay(10);

    /* Empty cell or bus glitch: keep RAM, never save 0 over a good value. */
    if (buf[0] == 0xFF && buf[1] == 0xFF) {
        if (previous_low != 0U && low == 0U) {
            low = previous_low;
            loww[0] = (uint8_t)((low >> 8) & 0xFF);
            loww[1] = (uint8_t)(low & 0xFF);
        }
        return;
    }

    {
        uint16_t raw = (uint16_t)((buf[0] << 8) | buf[1]);
        if (raw == 0U || raw == 2U) {
            if (previous_low != 0U && previous_low != 2U) {
                low = previous_low;
                loww[0] = (uint8_t)((low >> 8) & 0xFF);
                loww[1] = (uint8_t)(low & 0xFF);
            }
            return;
        }
        if (raw > LOW_VALUE_MAX) {
            raw = LOW_VALUE_MAX;
        }
        low = raw;
        loww[0] = (uint8_t)((low >> 8) & 0xFF);
        loww[1] = (uint8_t)(low & 0xFF);
        previous_low = low;
    }
}

void eeprom_save_low_value(void) {
    if (low == 0U && previous_low != 0U) {
        return;
    }
    if (HAL_I2C_IsDeviceReady(&hi2c1, 0x50 << 1, 1, 10) == HAL_OK) {
        HAL_I2C_Mem_Write(&hi2c1, 0x50 << 1, EEPROM_ADDR_LOW, I2C_MEMADD_SIZE_16BIT,
                          loww, 2, 1000);
        HAL_Delay(10);
        HAL_I2C_IsDeviceReady(&hi2c1, 0x50 << 1, 20, 10);
        if (mode == 0x4e && (current_page == 1U || current_page == 2U)) {
            eeprom_save_current_page(2U);
        }
    } else {
        eeprom_err = true;
    }
}

static uint8_t i2c_eeprom_read16(uint16_t addr, uint8_t *buf) {
    buf[0] = 0xFF;
    buf[1] = 0xFF;
    if (HAL_I2C_IsDeviceReady(&hi2c1, 0x50 << 1, 2, 20) != HAL_OK) {
        return 0;
    }
    if (HAL_I2C_Mem_Read(&hi2c1, 0x50 << 1, addr, I2C_MEMADD_SIZE_16BIT, buf, 2, 200) != HAL_OK) {
        return 0;
    }
    HAL_Delay(5);
    return 1;
}

static void eeprom_apply_brightness(uint16_t val) {
    if (val == 0 || val == 0xFFFF || val > 100) {
        val = DEFAULT_BRIGHTNESS;
    } else if (val < MIN_BRIGHTNESS) {
        val = MIN_BRIGHTNESS;
    }
    brightnes = val;
    brightness[0] = 0x00;
    brightness[1] = (uint8_t)val;
}

static void eeprom_save_brightness(void) {
    if (HAL_I2C_IsDeviceReady(&hi2c1, 0x50 << 1, 1, 10) == HAL_OK) {
        HAL_I2C_Mem_Write(&hi2c1, 0x50 << 1, 0x0100, I2C_MEMADD_SIZE_16BIT,
                          brightness, 2, 1000);
        HAL_Delay(10);
    }
}

void eeprom_read_brightness(void) {
    eeprom_apply_brightness(DEFAULT_BRIGHTNESS);

    if (!i2c_eeprom_read16(0x0100, brightness)) {
        eeprom_save_brightness();
        return;
    }

    uint16_t val = (uint16_t)((brightness[0] << 8) | brightness[1]);
    if (val == 0xFFFF || (brightness[0] == 0xFF && brightness[1] == 0xFF)) {
        eeprom_save_brightness();
        return;
    }

    uint16_t before = val;
    eeprom_apply_brightness(val);
    if (brightnes != before) {
        eeprom_save_brightness();
    }
}

static void dwin_send_brightness_quick(void) {
    uint8_t v = (uint8_t)brightnes;
    if (v < MIN_BRIGHTNESS) {
        v = MIN_BRIGHTNESS;
    }
    uint8_t cmd[7] = {0x5A, 0xA5, 0x04, 0x82, 0x00, 0x82, v};
    dwin_uart_send(cmd, 7);
}

void dwin_send_brightness(void) {
    uint8_t v = (uint8_t)brightnes;
    if (v < MIN_BRIGHTNESS) {
        v = MIN_BRIGHTNESS;
        brightnes = v;
        brightness[1] = v;
    }

    /* DWIN spec: 5A A5 04 82 00 82 VV — value in one byte, not 00 VV */
    dwin_send_brightness_quick();
    HAL_Delay(20);

    /* Alternate: duplicate data bytes VV VV */
    uint8_t cmd_dup[8] = {0x5A, 0xA5, 0x05, 0x82, 0x00, 0x82, v, v};
    dwin_uart_send(cmd_dup, 8);
}

static void dwin_disable_backlight_standby(void) {
    /* VP 0x0080: bit2=0 standby off, bit3=1 touch buzzer ON (0x30 mutes buzzer) */
    uint8_t cmd[10] = {0x5A, 0xA5, 0x07, 0x82, 0x00, 0x80, 0x5A, 0x00, 0x00, 0x38};
    dwin_uart_send(cmd, 10);
}

static void brightness_user_changed(uint16_t requested) {
    if (requested > 100U) {
        return;
    }

    uint16_t before = brightnes;
    eeprom_apply_brightness(requested);
    if (brightnes == before) {
        return;
    }

    eeprom_save_brightness();
    brightness_user_touched = 1;
    brightness_display_push_until = 0;

    if (requested < MIN_BRIGHTNESS) {
        dwin_send_brightness_quick();
    }
}

static void brightness_handle_rx(uint16_t reported) {
    if (HAL_GetTick() < brightness_save_enable_tick) {
        return;
    }
    brightness_user_changed(reported);
}

static void dwin_poll_brightness(void) {
    static uint32_t last_poll = 0;

    if (dwin_tx_user_adjust_quiet()) {
        return;
    }
    if (HAL_GetTick() < brightness_save_enable_tick) {
        return;
    }
    if (HAL_GetTick() - last_poll < 800U) {
        return;
    }
    last_poll = HAL_GetTick();

    uint8_t cmd[7] = {0x5A, 0xA5, 0x04, 0x83, 0x00, 0x82, 0x01};
    dwin_uart_send(cmd, 7);
}

/* VP 0x1000 (low, Variable Icon) does not auto-upload, so the MCU reads it. */
static void dwin_poll_low(void) {
    static uint32_t last = 0;
    if (mode != 0x4eU) {
        return;
    }
    /* Only the low settings page needs live polling; page 6 shows a fixed value. */
    if (current_page != PAGE_LOW_SET) {
        return;
    }
    /* Never transmit right after a received byte — a mode-key packet may still be
       arriving, and dwin_uart_send aborts RX. Wait for the line to go quiet. */
    if (HAL_GetTick() - last_rx_tick < 250U) {
        return;
    }
    if (HAL_GetTick() - last < 250U) {
        return;
    }
    last = HAL_GetTick();
    uint8_t cmd[7] = {0x5A, 0xA5, 0x04, 0x83,
                      (uint8_t)((VP_LOW_VALUE >> 8) & 0xFF),
                      (uint8_t)(VP_LOW_VALUE & 0xFF), 0x01};
    dwin_uart_send(cmd, 7);
}

void dwin_refresh_brightness(void) {
    eeprom_read_brightness();
    brightness_user_touched = 0;
    brightness_display_push_until = HAL_GetTick() + 8000;
    brightness_save_enable_tick = HAL_GetTick() + 500;
    dwin_disable_backlight_standby();
    dwin_send_brightness();
}

void eeprom_read_vp3003_value(void) {
    /* Separate EEPROM: high @ 0x0014, bipolar @ 0x0018. Never mix the two. */
    if (!high_eeprom_dirty) {
        eeprom_read_hibi_slot(0x4fU);
    }
    if (!bipolar_eeprom_dirty) {
        eeprom_read_hibi_slot(0x4dU);
    }
    vp3003_bind_active();
}

static void vp3003_bind_active(void) {
    uint16_t v;

    if (mode == 0x4fU) {
        if (high == 0U && previous_high != 0U) {
            high = previous_high;
        }
        v = hibi_clamp(high);
        high = v;
        highh[0] = (uint8_t)((v >> 8) & 0xFF);
        highh[1] = (uint8_t)(v & 0xFF);
    } else if (mode == 0x4dU) {
        if (bipolar == 0U && previous_bipolar != 0U) {
            bipolar = previous_bipolar;
        }
        v = hibi_clamp(bipolar);
        bipolar = v;
        bipolarr[0] = (uint8_t)((v >> 8) & 0xFF);
        bipolarr[1] = (uint8_t)(v & 0xFF);
    } else {
        return;
    }
    vp3003_val = v;
    vp3003w[0] = (uint8_t)((v >> 8) & 0xFF);
    vp3003w[1] = (uint8_t)(v & 0xFF);
}

static void hibi_persist_now(uint16_t which_mode) {
    if (which_mode == 0x4fU) {
        eeprom_save_hibi_slot(0x4fU);
        high_eeprom_dirty = 0;
    } else if (which_mode == 0x4dU) {
        eeprom_save_hibi_slot(0x4dU);
        bipolar_eeprom_dirty = 0;
    }
}

/* Force-save high, bipolar, and low so reboot restores every state value. */
static void eeprom_persist_all_values(void) {
    eeprom_save_hibi_slot(0x4fU);
    high_eeprom_dirty = 0;
    eeprom_save_hibi_slot(0x4dU);
    bipolar_eeprom_dirty = 0;
    low_persist_now();
}

static void eeprom_save_mode_now(void) {
    modee[0] = EEPROM_MODE_MAGIC;
    modee[1] = (uint8_t)mode;
    if (HAL_I2C_IsDeviceReady(&hi2c1, 0x50 << 1, 1, 10) == HAL_OK) {
        HAL_I2C_Mem_Write(&hi2c1, 0x50 << 1, EEPROM_ADDR_MODE,
                          I2C_MEMADD_SIZE_16BIT, modee, 2, 1000);
        HAL_Delay(10);
    } else {
        eeprom_err = true;
    }
}

static void eeprom_persist_leaving_state(uint16_t old_mode) {
    if (old_mode == 0x4fU || old_mode == 0x4dU) {
        hibi_persist_now(old_mode);
    } else if (old_mode == 0x4eU) {
        low_persist_now();
    }
}

static void eeprom_save_hibi_slot(uint16_t which_mode) {
    if (HAL_I2C_IsDeviceReady(&hi2c1, 0x50 << 1, 1, 10) != HAL_OK) {
        eeprom_err = true;
        return;
    }
    if (which_mode == 0x4fU) {
        if (high == 0U) {
            if (previous_high != 0U) {
                high = previous_high;
            } else {
                return;
            }
        }
        previous_high = high;
        highh[0] = (uint8_t)((high >> 8) & 0xFF);
        highh[1] = (uint8_t)(high & 0xFF);
        HAL_I2C_Mem_Write(&hi2c1, 0x50 << 1, EEPROM_ADDR_HIGH,
                          I2C_MEMADD_SIZE_16BIT, highh, 2, 1000);
        HAL_Delay(10);
    } else if (which_mode == 0x4dU) {
        if (bipolar == 0U) {
            if (previous_bipolar != 0U) {
                bipolar = previous_bipolar;
            } else {
                return;
            }
        }
        previous_bipolar = bipolar;
        bipolarr[0] = (uint8_t)((bipolar >> 8) & 0xFF);
        bipolarr[1] = (uint8_t)(bipolar & 0xFF);
        HAL_I2C_Mem_Write(&hi2c1, 0x50 << 1, EEPROM_ADDR_BIPOLAR,
                          I2C_MEMADD_SIZE_16BIT, bipolarr, 2, 1000);
        HAL_Delay(10);
    }
}

static void eeprom_read_hibi_slot(uint16_t which_mode) {
    uint8_t buf[2];
    uint16_t v;

    if (which_mode != 0x4fU && which_mode != 0x4dU) {
        return;
    }
    if (!i2c_eeprom_read16((which_mode == 0x4fU) ? EEPROM_ADDR_HIGH : EEPROM_ADDR_BIPOLAR,
                           buf)) {
        return;
    }
    if (buf[0] == 0xFF && buf[1] == 0xFF) {
        return;
    }
    v = hibi_clamp((uint16_t)((buf[0] << 8) | buf[1]));
    if (v == 0U) {
        return;
    }
    if (which_mode == 0x4fU) {
        high = v;
        previous_high = v;
        highh[0] = (uint8_t)((v >> 8) & 0xFF);
        highh[1] = (uint8_t)(v & 0xFF);
    } else {
        bipolar = v;
        previous_bipolar = v;
        bipolarr[0] = (uint8_t)((v >> 8) & 0xFF);
        bipolarr[1] = (uint8_t)(v & 0xFF);
    }
}

static uint8_t vp3003_is_page_default(uint16_t val) {
    if (val == 0) {
        return 1;
    }
    if ((mode == 0x4f || mode == 0x4d) && val == INPUT_MAX_HIBI) {
        return 1;
    }
    return 0;
}

static void vp3003_stop_push(void) {
    vp3003_page1_restore_until = 0;
    vp3003_save_enable_tick = 0;
}

/* Show the active high/bipolar RAM value on VP 0x3003 immediately (EEPROM later). */
static void vp3003_paint_active_fast(void) {
    vp3003_user_touched = 0;
    vp3003_last_accept_tick = 0U;
    vp3003_rx_ignore_until = HAL_GetTick() + 800U;
    dwin_set_var_icon(var_icon_from_mode(mode));
    vp3003_bind_active();
    send_variable_data(0x30, 0x00, modee[0], modee[1]);
    send_var_icon_fast();
    vp3003_push_display_burst(3);
}

static void vp3003_apply_mode_key(uint16_t new_mode) {
    uint16_t old_mode = mode;

    new_mode = mode_normalize(new_mode);
    if (new_mode == 0U) {
        return;
    }

    mode = new_mode;
    modee[0] = EEPROM_MODE_MAGIC;
    modee[1] = (uint8_t)new_mode;
    previous_mode = new_mode;
    dwin_set_var_icon(var_icon_from_mode(new_mode));
    var_icon_user_locked = 1;

    /* Paint first for smooth switch; EEPROM after (same separate slots). */
    if (new_mode == 0x4fU || new_mode == 0x4dU) {
        vp3003_paint_active_fast();
        if (current_page != PAGE_HIBI_SET) {
            dwin_show_settings_page(1U);
        } else {
            eeprom_save_current_page(1U);
            send_var_icon_fast();
            vp3003_push_display_burst(2);
        }
    }

    if (old_mode != new_mode) {
        eeprom_persist_leaving_state(old_mode);
    }
    eeprom_save_mode_now();
    eeprom_save_var_icon();
    var_icon_user_locked = 1;
}

static uint8_t vp3003_is_mode_return_key(uint16_t val) {
    return (var_icon_from_mode_key(val) != 0U);
}

static void var_icon_apply_return_key(uint16_t key) {
    uint8_t icon_id = var_icon_from_mode_key(key);
    if (icon_id == 0U) {
        return;
    }

    dwin_set_var_icon(icon_id);
    var_icon_user_locked = 1;

    if (key == MODE_KEY_HIGH || key == 0x004f || key == 0x4f) {
        vp3003_apply_mode_key(0x4f);
    } else if (key == MODE_KEY_LOW || key == 0x004e || key == 0x4e) {
        uint16_t old_mode = mode;
        mode = 0x4e;
        modee[0] = EEPROM_MODE_MAGIC;
        modee[1] = 0x4e;
        previous_mode = 0x4e;
        dwin_set_var_icon(ICON_LOW);
        var_icon_user_locked = 1;
        send_variable_data(0x30, 0x00, modee[0], modee[1]);
        send_var_icon_fast();
        dwin_show_settings_page(2U);
        if (old_mode != 0x4eU) {
            eeprom_persist_leaving_state(old_mode);
        }
        eeprom_save_mode_now();
        eeprom_save_current_page(2U);
        eeprom_save_var_icon();
        var_icon_user_locked = 1;
    } else {
        vp3003_apply_mode_key(0x4d);
    }

    send_var_icon_fast();
}

/* During user +/- hold: listen only — do not write the old number back. */
static void vp3003_handle_page1_rx(uint16_t new_val) {
    if (mode != 0x4fU && mode != 0x4dU) {
        return;
    }
    /* After high<->bipolar switch, ignore leftover VP 0x3003 echo / page default 0. */
    if (HAL_GetTick() < vp3003_rx_ignore_until) {
        return;
    }
    if (new_val > INPUT_MAX_HIBI) {
        return;
    }
    if (new_val == 0U) {
        return;
    }
    if (HAL_GetTick() < vp3003_save_enable_tick && vp3003_is_page_default(new_val)) {
        return;
    }
    /* Shared VP 0x3003: do not copy high's increment into bipolar, or bipolar into high. */
    if (mode == 0x4fU && new_val == bipolar && new_val != high) {
        return;
    }
    if (mode == 0x4dU && new_val == high && new_val != bipolar) {
        return;
    }
    vp3003_user_touched = 1;
    vp3003_last_accept_tick = HAL_GetTick();
    vp3003_stop_push();
    var_icon_aggressive_until = 0;
    var_icon_display_push_until = 0;
    var_icon_boot_push_until = 0;
    vp3003_user_changed(new_val);
    vp3003_display_pending = 1;
}

void vp3003_send_to_display(void) {
    if (dwin_tx_page1_quiet()) {
        return;
    }
    vp3003_send_to_display_force();
}

static void vp3003_send_to_display_force(void) {
    uint8_t cmd[8] = {
        0x5A, 0xA5, 0x05, 0x82,
        (uint8_t)((VP_MODE_DATA >> 8) & 0xFF),
        (uint8_t)(VP_MODE_DATA & 0xFF),
        vp3003w[0], vp3003w[1]
    };
    dwin_uart_send(cmd, 8);
}

static void vp3003_display_flush(void) {
    if (!vp3003_display_pending) {
        return;
    }
    if (dwin_tx_page1_quiet()) {
        return;
    }
    vp3003_display_pending = 0;
    vp3003_send_to_display_force();
}

static void vp3003_eeprom_flush(void) {
    uint32_t now = HAL_GetTick();
    if (high_eeprom_dirty && (int32_t)(now - high_eeprom_save_deadline) >= 0) {
        hibi_persist_now(0x4fU);
    }
    if (bipolar_eeprom_dirty && (int32_t)(now - bipolar_eeprom_save_deadline) >= 0) {
        hibi_persist_now(0x4dU);
    }
}

static void vp3003_push_display_burst(uint8_t count) {
    vp3003_bind_active();
    vp3003_last_accept_tick = 0U;
    while (count > 0U) {
        vp3003_send_to_display_force();
        count--;
    }
}

static void vp3003_hold_service(void) {
    static uint32_t last_show_ms;
    uint32_t now;

    if (current_page != 1U) {
        return;
    }
    if (mode != 0x4fU && mode != 0x4dU) {
        return;
    }
    if (vp3003_user_touched || dwin_tx_page1_quiet()) {
        return;
    }
    if (HAL_GetTick() >= vp3003_page1_restore_until) {
        return;
    }
    now = HAL_GetTick();
    if ((now - last_show_ms) >= 250U) {
        vp3003_bind_active();
        vp3003_send_to_display_force();
        last_show_ms = now;
    }
}

void vp3003_user_changed(uint16_t new_val) {
    if (mode != 0x4fU && mode != 0x4dU) {
        return;
    }
    if (new_val > INPUT_MAX_HIBI) {
        return;
    }
    if (new_val == 0U) {
        return;
    }
    if (new_val == INPUT_MAX_HIBI && vp3003_val < (INPUT_MAX_HIBI - 3) &&
        (HAL_GetTick() < vp3003_save_enable_tick)) {
        return;
    }

    if (mode == 0x4fU) {
        if (new_val == high) {
            vp3003_bind_active();
            return;
        }
        high = new_val;
        previous_high = new_val;
        highh[0] = (uint8_t)((high >> 8) & 0xFF);
        highh[1] = (uint8_t)(high & 0xFF);
        high_eeprom_dirty = 1;
        high_eeprom_save_deadline = HAL_GetTick() + 150;
    } else {
        if (new_val == bipolar) {
            vp3003_bind_active();
            return;
        }
        bipolar = new_val;
        previous_bipolar = new_val;
        bipolarr[0] = (uint8_t)((bipolar >> 8) & 0xFF);
        bipolarr[1] = (uint8_t)(bipolar & 0xFF);
        bipolar_eeprom_dirty = 1;
        bipolar_eeprom_save_deadline = HAL_GetTick() + 150;
    }
    vp3003_bind_active();
    hibi_persist_now(mode);
}

static void dwin_after_page_values(uint8_t page_num) {
    send_variable_data(0x30, 0x00, modee[0], modee[1]);
    dwin_set_var_icon(var_icon_from_mode(mode));
    if (page_num == PAGE_HIBI_SET || page_num == PAGE_LOW_SET) {
        dwin_icon_burst_fast(2);
    }
    if (page_num == PAGE_HIBI_SET || page_num == PAGE_HIGH_RUN ||
        page_num == PAGE_BIPOLAR_RUN) {
        vp3003_bind_active();
        vp3003_push_display_burst(4);
    }
    if (page_num == PAGE_LOW_SET) {
        low_burst_vp1000(4);
    }
    if (page_num == PAGE_LOW_RUN) {
        low_burst_vp1000(4);
        low_burst_vp3002(4);
    }
}

void low_sync_both_vps(void) {
    if (dwin_tx_low_quiet()) {
        low_push_vp3002_only();
        return;
    }
    low_push_vps_fast();
}

void low_push_display_from_eeprom(void) {
    eeprom_read_low_value();
    low_sync_both_vps();
    previous_low = low;
}

void low_send_to_display(void) {
    low_push_display_from_eeprom();
}

static void dwin_arm_var_icon_timers(void) {
    var_icon_save_enable_tick = HAL_GetTick() + 5000;
    var_icon_display_push_until = HAL_GetTick() + 15000;
    var_icon_boot_push_until = HAL_GetTick() + 20000;
    var_icon_aggressive_until = HAL_GetTick() + 3000;
    eeprom_read_var_icon();
}

static void dwin_arm_page2_restore_timers(void) {
    low_save_enable_tick = HAL_GetTick() + 2000;
    var_icon_save_enable_tick = HAL_GetTick() + 2000;
    var_icon_aggressive_until = HAL_GetTick() + 1500;
    var_icon_display_push_until = 0;
    var_icon_boot_push_until = 0;
    low_display_push_until = HAL_GetTick() + 2000;
    low_hold_stream = 0;
    low_hold_last_rx_ms = 0;
    low_hold_step_ms = 0;
}

static void dwin_push_icon_from_eeprom(void) {
    eeprom_read_var_icon();
    send_var_icon_to_display();
}

static void dwin_icon_burst_fast(uint8_t count) {
    while (count > 0U) {
        send_var_icon_fast();
        count--;
    }
}

static void dwin_icon_burst_from_eeprom(uint8_t count) {
    eeprom_read_var_icon();
    dwin_icon_burst_fast(count);
}

static void dwin_restore_var_icon_from_eeprom(uint8_t burst_count) {
    dwin_arm_var_icon_timers();
    eeprom_read_var_icon();
    if (burst_count > 0U) {
        dwin_icon_burst_fast(burst_count);
    } else {
        send_var_icon_fast();
    }
}

static void dwin_push_page2_from_eeprom(void) {
    if (!low_eeprom_dirty) {
        eeprom_read_low_value();
    }
    if (low == 0U && previous_low != 0U) {
        low = previous_low;
        loww[0] = (uint8_t)((low >> 8) & 0xFF);
        loww[1] = (uint8_t)(low & 0xFF);
    } else if (low != 0U) {
        previous_low = low;
    }
    low_burst_vp1000(4);
    eeprom_read_var_icon();
    dwin_icon_burst_fast(2);
}

static void dwin_restore_page_from_eeprom(uint8_t page_num) {
    if (page_num == 1U) {
        vp3003_user_touched = 0;
        vp3003_last_accept_tick = 0U;
        vp3003_save_enable_tick = HAL_GetTick() + 400;
        vp3003_page1_restore_until = HAL_GetTick() + 5000;
        vp3003_rx_ignore_until = HAL_GetTick() + 800U;
        vp3003_bind_active();
        vp3003_push_display_burst(3);
        eeprom_read_var_icon();
        dwin_icon_burst_fast(2);
    } else if (page_num == 2U) {
        dwin_arm_page2_restore_timers();
        dwin_push_page2_from_eeprom();
    }
}

static void dwin_show_settings_page(uint8_t page_num) {
    if (page_num != 1U && page_num != 2U) {
        return;
    }

    if (page_num == 2U) {
        /* Prefer RAM for instant paint; EEPROM already loaded at boot / last edit. */
        if (low == 0U && previous_low != 0U) {
            low = previous_low;
            loww[0] = (uint8_t)((low >> 8) & 0xFF);
            loww[1] = (uint8_t)(low & 0xFF);
        } else if (low != 0U) {
            previous_low = low;
        }
    } else {
        vp3003_bind_active();
    }

    if (current_page != page_num) {
        send_page_change(page_num);
    } else {
        eeprom_save_current_page(page_num);
        send_var_icon_fast();
    }

    if (page_num == 2U) {
        if (!low_eeprom_dirty) {
            dwin_arm_page2_restore_timers();
        }
        low_burst_vp1000(4);
        send_var_icon_fast();
        low_burst_vp1000(2);
    } else {
        dwin_arm_var_icon_timers();
        dwin_restore_page_from_eeprom(1U);
        vp3003_push_display_burst(2);
        send_var_icon_fast();
    }
}

void dwin_refresh_page2_values(void) {
    if (!low_eeprom_dirty) {
        dwin_arm_page2_restore_timers();
        eeprom_read_low_value();
    }
    if (low == 0U && previous_low != 0U) {
        low = previous_low;
        loww[0] = (uint8_t)((low >> 8) & 0xFF);
        loww[1] = (uint8_t)(low & 0xFF);
    } else if (low != 0U) {
        previous_low = low;
    }
    eeprom_read_var_icon();
    low_burst_vp1000(4);
    dwin_icon_burst_fast(3);
}

void dwin_refresh_page1_values(void) {
    vp3003_paint_active_fast();
    eeprom_read_var_icon();
    send_var_icon_fast();
}

void dwin_restore_saved_state(uint8_t page_num) {
    /* PICSET already done. Paint last mode + saved values immediately. */
    current_page = page_num;
    saved_settings_page = page_num;

    dwin_set_var_icon(var_icon_from_mode(mode));
    send_variable_data(0x30, 0x00, modee[0], modee[1]);
    send_var_icon_fast();
    dwin_after_page_values(page_num);

    brightness_user_touched = 0;
    dwin_disable_backlight_standby();
    dwin_send_brightness_quick();
    brightness_save_enable_tick = HAL_GetTick() + 500;
    brightness_display_push_until = HAL_GetTick() + 2000;
}

void dwin_open_page1(void) {
    dwin_show_settings_page(1U);
}

void dwin_open_page2(void) {
    dwin_show_settings_page(2U);
}

void dwin_apply_boot_var_icon(void) {
    eeprom_read_var_icon();
    dwin_arm_var_icon_timers();
    dwin_icon_burst_fast(4);
}
/* USER CODE END 0 */

int main(void)
{

  /* MCU Configuration--------------------------------------------------------*/

    HAL_Init();

  SystemClock_Config();

  MX_GPIO_Init();
  MX_DMA_Init();
  MX_ADC1_Init();
  MX_TIM3_Init();
  MX_TIM4_Init();
  MX_I2C1_Init();
  MX_USART3_UART_Init();
  MX_TIM1_Init();

  /* USER CODE BEGIN 2 */
  HAL_ADCEx_Calibration_Start(&hadc1);
  HAL_ADC_Start_DMA(&hadc1, (uint32_t *)adc_dma_buf, 2);

  HAL_Delay(200);

  low_save_enable_tick = HAL_GetTick() + 2000U;
  vp3003_save_enable_tick = HAL_GetTick() + 2000U;

  /* Read EEPROM before any display UART */
  eeprom_read_low_value();
  if (low == 0U) {
      HAL_Delay(80);
      eeprom_read_low_value();
  }
  eeprom_read_saved_page();
  eeprom_read_vp3003_value();

  i2c_eeprom_read16(EEPROM_ADDR_MODE, modee);
  mode = mode_normalize((uint16_t)((modee[0] << 8) | modee[1]));
  eeprom_read_var_icon();
  if (mode == 0U) {
      mode = mode_from_icon(var_icon_value);
  }
  if (mode == 0U) {
      mode = 0x4eU;
  }
  previous_mode = mode;
  dwin_set_var_icon(var_icon_from_mode(mode));
  vp3003_bind_active();

  eeprom_read_brightness();

  {
  uint8_t boot_page = dwin_get_boot_page();

  dwin_boot_to_page(boot_page);

  HAL_TIM_PWM_Start(&htim3, TIM_CHANNEL_1);
  HAL_TIM_PWM_Start(&htim4, TIM_CHANNEL_3);
  HAL_TIM_PWM_Start(&htim1, TIM_CHANNEL_1);
  __HAL_TIM_SET_COMPARE(&htim1, TIM_CHANNEL_1, 500);
  __HAL_TIM_SET_COMPARE(&htim4, TIM_CHANNEL_3, 300);

  dwin_restore_saved_state(boot_page);
  dwin_uart_rx_start();
  boot_page_guard_until = 0;
  previous_mode = mode;
  HAL_Delay(40);
  dwin_after_page_values(boot_page);
  }
  /* USER CODE END 2 */

  /* Infinite loop */
  while (1) {

    /* USER CODE BEGIN 3 */
    /* Skip 1 ms wait while user adjusts +/- so UART packets are not missed */
    if (!(dwin_tx_page1_quiet() ||
          ((current_page == 1U || current_page == 2U) && mode == 0x4e && low_user_touched))) {
        HAL_Delay(1);
    }

    if (dwin_pkt_ready) {
        dwin_pkt_ready = 0;
    }

    {
        uint8_t pkt_len;

        while ((pkt_len = dwin_rx_queue_pop(RxData, sizeof(RxData))) != 0U) {
            uint16_t rx_addr = 0;
            uint16_t rx_data = 0;
            uint8_t rx_valid = 0;

            dwin_rx_get_vp(&rx_addr, &rx_data, &rx_valid);
            if (rx_valid) {
                address = rx_addr;
                dataa = rx_data;
                number_eeprome_flag = true;
                prev_address = address;
                prev_dataa = dataa;
                save_reading();
            }
        }

        low_hold_service();
        vp3003_hold_service();
        dwin_rx_collect_packets();

        while ((pkt_len = dwin_rx_queue_pop(RxData, sizeof(RxData))) != 0U) {
            uint16_t rx_addr = 0;
            uint16_t rx_data = 0;
            uint8_t rx_valid = 0;

            dwin_rx_get_vp(&rx_addr, &rx_data, &rx_valid);
            if (rx_valid) {
                address = rx_addr;
                dataa = rx_data;
                number_eeprome_flag = true;
                prev_address = address;
                prev_dataa = dataa;
                save_reading();
            }
        }
        low_hold_service();
        vp3003_hold_service();
    }

    if (!dwin_tx_user_adjust_quiet()) {
        if (current_page != 2U) {
            if (HAL_GetTick() < var_icon_aggressive_until) {
                send_var_icon_fast();
            } else if (HAL_GetTick() < var_icon_boot_push_until) {
                static uint32_t last_boot_icon = 0;
                if (HAL_GetTick() - last_boot_icon >= 30) {
                    send_var_icon_fast();
                    last_boot_icon = HAL_GetTick();
                }
            } else if (HAL_GetTick() < var_icon_display_push_until) {
                static uint32_t last_icon_push = 0;
                if (HAL_GetTick() - last_icon_push >= 80) {
                    dwin_push_icon_from_eeprom();
                    last_icon_push = HAL_GetTick();
                }
            }
        } else if (HAL_GetTick() < var_icon_aggressive_until && !low_user_touched) {
            send_var_icon_fast();
        }
    }

    if (current_page == 2U && !low_user_touched && !low_eeprom_dirty &&
        !dwin_tx_low_quiet() &&
        HAL_GetTick() < low_display_push_until) {
        static uint32_t last_low_push = 0;
        if (HAL_GetTick() - last_low_push >= 350) {
            if (low == 0U && previous_low != 0U) {
                low = previous_low;
                loww[0] = (uint8_t)((low >> 8) & 0xFF);
                loww[1] = (uint8_t)(low & 0xFF);
            }
            low_push_vp3002_only();
            last_low_push = HAL_GetTick();
        }
    } else if (!brightness_user_touched &&
               HAL_GetTick() < brightness_display_push_until) {
        static uint32_t last_brightness_push = 0;
        if (HAL_GetTick() - last_brightness_push >= 800) {
            dwin_send_brightness_quick();
            last_brightness_push = HAL_GetTick();
        }
    }

    if (current_page == 1 && !vp3003_user_touched &&
        HAL_GetTick() < vp3003_page1_restore_until) {
        static uint32_t last_vp3003_push = 0;
        if (HAL_GetTick() - last_vp3003_push >= 200) {
            vp3003_bind_active();
            vp3003_send_to_display_force();
            last_vp3003_push = HAL_GetTick();
        }
    }

    low_display_flush();
    vp3003_display_flush();

    count++;

    save_reading();
    send_loadings();
    low_eeprom_flush();
    vp3003_eeprom_flush();

    dwin_poll_brightness();
    dwin_poll_low();

    debouncing();
    hv_adc_reading();

    uint8_t triggered = ((footswitch) || (active)) ? 1U : 0U;
    uint8_t output_ok = (triggered && (alert_hv == 0) && (alert_gate == 0)) ? 1U : 0U;

    if (triggered) {
        /* Trigger always shows the run page (4/5/6). HV energizing (PWM +
           hv_en + relays) stays gated by the ADC safety check (output_ok). */
        ch_pg_flag = true;

        if (output_ok) {
            HAL_TIM_PWM_Start(&htim3, TIM_CHANNEL_1);
            HAL_TIM_PWM_Start(&htim4, TIM_CHANNEL_3);
            HAL_TIM_PWM_Start(&htim1, TIM_CHANNEL_1);
            HAL_GPIO_WritePin(hv_en_GPIO_Port, hv_en_Pin, GPIO_PIN_RESET);
        } else {
            HAL_TIM_PWM_Stop(&htim3, TIM_CHANNEL_1);
            HAL_TIM_PWM_Stop(&htim4, TIM_CHANNEL_3);
            HAL_TIM_PWM_Stop(&htim1, TIM_CHANNEL_1);
            HAL_GPIO_WritePin(hv_en_GPIO_Port, hv_en_Pin, GPIO_PIN_SET);
        }

        switch (mode) {
        case 0x4f:
            if (output_ok) {
                bi_hi_pwm(high);
                HAL_GPIO_WritePin(GPIOA, highrly_Pin, GPIO_PIN_SET);
                HAL_GPIO_WritePin(GPIOA, biprly_Pin, GPIO_PIN_RESET);
                HAL_GPIO_WritePin(GPIOA, lowrly_Pin, GPIO_PIN_RESET);
            } else {
                HAL_GPIO_WritePin(GPIOA, biprly_Pin|highrly_Pin|lowrly_Pin, GPIO_PIN_RESET);
            }
            if (current_page != PAGE_HIGH_RUN) {
                send_page_change(PAGE_HIGH_RUN);
            } else {
                static uint32_t last_high_run_push;
                if (HAL_GetTick() - last_high_run_push >= 200U) {
                    vp3003_bind_active();
                    vp3003_send_to_display_force();
                    last_high_run_push = HAL_GetTick();
                }
            }
            break;
        case 0x4e:
            if (output_ok) {
                lowfunction(low);
                HAL_GPIO_WritePin(GPIOA, lowrly_Pin, GPIO_PIN_SET);
                HAL_GPIO_WritePin(GPIOA, biprly_Pin, GPIO_PIN_RESET);
                HAL_GPIO_WritePin(GPIOA, highrly_Pin, GPIO_PIN_RESET);
            } else {
                HAL_GPIO_WritePin(GPIOA, biprly_Pin|highrly_Pin|lowrly_Pin, GPIO_PIN_RESET);
            }
            if (current_page != PAGE_LOW_RUN) {
                send_page_change(PAGE_LOW_RUN);
            } else {
                static uint32_t last_low_run_push;
                if (HAL_GetTick() - last_low_run_push >= 200U) {
                    low_push_vp3002_only();
                    last_low_run_push = HAL_GetTick();
                }
            }
            break;
        case 0x4d:
            if (output_ok) {
                bi_hi_pwm(bipolar);
                HAL_GPIO_WritePin(GPIOA, biprly_Pin, GPIO_PIN_SET);
                HAL_GPIO_WritePin(GPIOA, lowrly_Pin, GPIO_PIN_RESET);
                HAL_GPIO_WritePin(GPIOA, highrly_Pin, GPIO_PIN_RESET);
            } else {
                HAL_GPIO_WritePin(GPIOA, biprly_Pin|highrly_Pin|lowrly_Pin, GPIO_PIN_RESET);
            }
            if (current_page != PAGE_BIPOLAR_RUN) {
                send_page_change(PAGE_BIPOLAR_RUN);
            } else {
                static uint32_t last_bip_run_push;
                if (HAL_GetTick() - last_bip_run_push >= 200U) {
                    vp3003_bind_active();
                    vp3003_send_to_display_force();
                    last_bip_run_push = HAL_GetTick();
                }
            }
            break;
        }
        hv_adc_reading();

    } else {
        HAL_TIM_PWM_Stop(&htim3, TIM_CHANNEL_1);
        HAL_TIM_PWM_Stop(&htim4, TIM_CHANNEL_3);
        HAL_TIM_PWM_Stop(&htim1, TIM_CHANNEL_1);
        HAL_GPIO_WritePin(hv_en_GPIO_Port, hv_en_Pin, GPIO_PIN_SET);
        HAL_GPIO_WritePin(GPIOA, highrly_Pin, GPIO_PIN_RESET);
        HAL_GPIO_WritePin(GPIOA, biprly_Pin, GPIO_PIN_RESET);
        HAL_GPIO_WritePin(GPIOA, lowrly_Pin, GPIO_PIN_RESET);

        if (ch_pg_flag) {
            ch_pg_flag = false;
            if ((mode == 0x4f) || (mode == 0x4d)) {
                dwin_open_page1();
            } else {
                dwin_open_page2();
            }
        }
    }
  }
  /* USER CODE END 3 */
}

void SystemClock_Config(void)
{
  RCC_OscInitTypeDef RCC_OscInitStruct = {0};
  RCC_ClkInitTypeDef RCC_ClkInitStruct = {0};
  RCC_PeriphCLKInitTypeDef PeriphClkInit = {0};

  RCC_OscInitStruct.OscillatorType = RCC_OSCILLATORTYPE_HSE;
  RCC_OscInitStruct.HSEState = RCC_HSE_ON;
  RCC_OscInitStruct.HSEPredivValue = RCC_HSE_PREDIV_DIV1;
  RCC_OscInitStruct.HSIState = RCC_HSI_ON;
  RCC_OscInitStruct.PLL.PLLState = RCC_PLL_ON;
  RCC_OscInitStruct.PLL.PLLSource = RCC_PLLSOURCE_HSE;
  RCC_OscInitStruct.PLL.PLLMUL = RCC_PLL_MUL9;
  if (HAL_RCC_OscConfig(&RCC_OscInitStruct) != HAL_OK)
  {
    RCC_OscInitStruct.OscillatorType = RCC_OSCILLATORTYPE_HSI;
    RCC_OscInitStruct.HSEState = RCC_HSE_OFF;
    RCC_OscInitStruct.HSIState = RCC_HSI_ON;
    RCC_OscInitStruct.PLL.PLLState = RCC_PLL_ON;
    RCC_OscInitStruct.PLL.PLLSource = RCC_PLLSOURCE_HSI_DIV2;
    RCC_OscInitStruct.PLL.PLLMUL = RCC_PLL_MUL16;
    if (HAL_RCC_OscConfig(&RCC_OscInitStruct) != HAL_OK)
    {
      Error_Handler();
    }
  }

  RCC_ClkInitStruct.ClockType = RCC_CLOCKTYPE_HCLK|RCC_CLOCKTYPE_SYSCLK
                              |RCC_CLOCKTYPE_PCLK1|RCC_CLOCKTYPE_PCLK2;
  RCC_ClkInitStruct.SYSCLKSource = RCC_SYSCLKSOURCE_PLLCLK;
  RCC_ClkInitStruct.AHBCLKDivider = RCC_SYSCLK_DIV1;
  RCC_ClkInitStruct.APB1CLKDivider = RCC_HCLK_DIV2;
  RCC_ClkInitStruct.APB2CLKDivider = RCC_HCLK_DIV1;

  if (HAL_RCC_ClockConfig(&RCC_ClkInitStruct, FLASH_LATENCY_2) != HAL_OK)
  {
    Error_Handler();
  }
  PeriphClkInit.PeriphClockSelection = RCC_PERIPHCLK_ADC;
  PeriphClkInit.AdcClockSelection = RCC_ADCPCLK2_DIV6;
  if (HAL_RCCEx_PeriphCLKConfig(&PeriphClkInit) != HAL_OK)
  {
    Error_Handler();
  }
}

static void MX_ADC1_Init(void)
{

  ADC_ChannelConfTypeDef sConfig = {0};

  hadc1.Instance = ADC1;
  hadc1.Init.ScanConvMode = ADC_SCAN_ENABLE;
  hadc1.Init.ContinuousConvMode = ENABLE;
  hadc1.Init.DiscontinuousConvMode = DISABLE;
  hadc1.Init.ExternalTrigConv = ADC_SOFTWARE_START;
  hadc1.Init.DataAlign = ADC_DATAALIGN_RIGHT;
  hadc1.Init.NbrOfConversion = 2;
  if (HAL_ADC_Init(&hadc1) != HAL_OK)
  {
    Error_Handler();
  }

  sConfig.Channel = ADC_CHANNEL_1;
  sConfig.Rank = ADC_REGULAR_RANK_1;
  sConfig.SamplingTime = ADC_SAMPLETIME_28CYCLES_5;
  if (HAL_ADC_ConfigChannel(&hadc1, &sConfig) != HAL_OK)
  {
    Error_Handler();
  }

  sConfig.Channel = ADC_CHANNEL_0;
  sConfig.Rank = ADC_REGULAR_RANK_2;
  if (HAL_ADC_ConfigChannel(&hadc1, &sConfig) != HAL_OK)
  {
    Error_Handler();
  }

}

static void MX_I2C1_Init(void)
{

  hi2c1.Instance = I2C1;
  hi2c1.Init.ClockSpeed = 50000;
  hi2c1.Init.DutyCycle = I2C_DUTYCYCLE_2;
  hi2c1.Init.OwnAddress1 = 0;
  hi2c1.Init.AddressingMode = I2C_ADDRESSINGMODE_7BIT;
  hi2c1.Init.DualAddressMode = I2C_DUALADDRESS_DISABLE;
  hi2c1.Init.OwnAddress2 = 0;
  hi2c1.Init.GeneralCallMode = I2C_GENERALCALL_DISABLE;
  hi2c1.Init.NoStretchMode = I2C_NOSTRETCH_DISABLE;
  if (HAL_I2C_Init(&hi2c1) != HAL_OK)
  {
    Error_Handler();
  }

}

static void MX_TIM1_Init(void)
{

  TIM_MasterConfigTypeDef sMasterConfig = {0};
  TIM_OC_InitTypeDef sConfigOC = {0};
  TIM_BreakDeadTimeConfigTypeDef sBreakDeadTimeConfig = {0};

  htim1.Instance = TIM1;
  htim1.Init.Prescaler = 44;
  htim1.Init.CounterMode = TIM_COUNTERMODE_UP;
  htim1.Init.Period = 999;
  htim1.Init.ClockDivision = TIM_CLOCKDIVISION_DIV1;
  htim1.Init.RepetitionCounter = 0;
  htim1.Init.AutoReloadPreload = TIM_AUTORELOAD_PRELOAD_DISABLE;
  if (HAL_TIM_PWM_Init(&htim1) != HAL_OK)
  {
    Error_Handler();
  }
  sMasterConfig.MasterOutputTrigger = TIM_TRGO_RESET;
  sMasterConfig.MasterSlaveMode = TIM_MASTERSLAVEMODE_DISABLE;
  if (HAL_TIMEx_MasterConfigSynchronization(&htim1, &sMasterConfig) != HAL_OK)
  {
    Error_Handler();
  }
  sConfigOC.OCMode = TIM_OCMODE_PWM1;
  sConfigOC.Pulse = 0;
  sConfigOC.OCPolarity = TIM_OCPOLARITY_HIGH;
  sConfigOC.OCNPolarity = TIM_OCNPOLARITY_HIGH;
  sConfigOC.OCFastMode = TIM_OCFAST_DISABLE;
  sConfigOC.OCIdleState = TIM_OCIDLESTATE_RESET;
  sConfigOC.OCNIdleState = TIM_OCNIDLESTATE_RESET;
  if (HAL_TIM_PWM_ConfigChannel(&htim1, &sConfigOC, TIM_CHANNEL_1) != HAL_OK)
  {
    Error_Handler();
  }
  sBreakDeadTimeConfig.OffStateRunMode = TIM_OSSR_DISABLE;
  sBreakDeadTimeConfig.OffStateIDLEMode = TIM_OSSI_DISABLE;
  sBreakDeadTimeConfig.LockLevel = TIM_LOCKLEVEL_OFF;
  sBreakDeadTimeConfig.DeadTime = 0;
  sBreakDeadTimeConfig.BreakState = TIM_BREAK_DISABLE;
  sBreakDeadTimeConfig.BreakPolarity = TIM_BREAKPOLARITY_HIGH;
  sBreakDeadTimeConfig.AutomaticOutput = TIM_AUTOMATICOUTPUT_DISABLE;
  if (HAL_TIMEx_ConfigBreakDeadTime(&htim1, &sBreakDeadTimeConfig) != HAL_OK)
  {
    Error_Handler();
  }
  HAL_TIM_MspPostInit(&htim1);

}

static void MX_TIM3_Init(void)
{

  TIM_MasterConfigTypeDef sMasterConfig = {0};
  TIM_OC_InitTypeDef sConfigOC = {0};

  htim3.Instance = TIM3;
  htim3.Init.Prescaler = 2;
  htim3.Init.CounterMode = TIM_COUNTERMODE_UP;
  htim3.Init.Period = 999;
  htim3.Init.ClockDivision = TIM_CLOCKDIVISION_DIV1;
  htim3.Init.AutoReloadPreload = TIM_AUTORELOAD_PRELOAD_ENABLE;
  if (HAL_TIM_PWM_Init(&htim3) != HAL_OK)
  {
    Error_Handler();
  }
  sMasterConfig.MasterOutputTrigger = TIM_TRGO_RESET;
  sMasterConfig.MasterSlaveMode = TIM_MASTERSLAVEMODE_DISABLE;
  if (HAL_TIMEx_MasterConfigSynchronization(&htim3, &sMasterConfig) != HAL_OK)
  {
    Error_Handler();
  }
  sConfigOC.OCMode = TIM_OCMODE_PWM1;
  sConfigOC.Pulse = 0;
  sConfigOC.OCPolarity = TIM_OCPOLARITY_HIGH;
  sConfigOC.OCFastMode = TIM_OCFAST_DISABLE;
  if (HAL_TIM_PWM_ConfigChannel(&htim3, &sConfigOC, TIM_CHANNEL_1) != HAL_OK)
  {
    Error_Handler();
  }
  HAL_TIM_MspPostInit(&htim3);

}

static void MX_TIM4_Init(void)
{

  TIM_MasterConfigTypeDef sMasterConfig = {0};
  TIM_OC_InitTypeDef sConfigOC = {0};

  htim4.Instance = TIM4;
  htim4.Init.Prescaler = 0;
  htim4.Init.CounterMode = TIM_COUNTERMODE_UP;
  htim4.Init.Period = 2999;
  htim4.Init.ClockDivision = TIM_CLOCKDIVISION_DIV1;
  htim4.Init.AutoReloadPreload = TIM_AUTORELOAD_PRELOAD_ENABLE;
  if (HAL_TIM_PWM_Init(&htim4) != HAL_OK)
  {
    Error_Handler();
  }
  sMasterConfig.MasterOutputTrigger = TIM_TRGO_RESET;
  sMasterConfig.MasterSlaveMode = TIM_MASTERSLAVEMODE_DISABLE;
  if (HAL_TIMEx_MasterConfigSynchronization(&htim4, &sMasterConfig) != HAL_OK)
  {
    Error_Handler();
  }
  sConfigOC.OCMode = TIM_OCMODE_PWM1;
  sConfigOC.Pulse = 1500;
  sConfigOC.OCPolarity = TIM_OCPOLARITY_HIGH;
  sConfigOC.OCFastMode = TIM_OCFAST_DISABLE;
  if (HAL_TIM_PWM_ConfigChannel(&htim4, &sConfigOC, TIM_CHANNEL_3) != HAL_OK)
  {
    Error_Handler();
  }
  HAL_TIM_MspPostInit(&htim4);

}

static void MX_USART3_UART_Init(void)
{

  huart3.Instance = USART3;
  huart3.Init.BaudRate = 115200;
  huart3.Init.WordLength = UART_WORDLENGTH_8B;
  huart3.Init.StopBits = UART_STOPBITS_1;
  huart3.Init.Parity = UART_PARITY_NONE;
  huart3.Init.Mode = UART_MODE_TX_RX;
  huart3.Init.HwFlowCtl = UART_HWCONTROL_NONE;
  huart3.Init.OverSampling = UART_OVERSAMPLING_16;
  if (HAL_UART_Init(&huart3) != HAL_OK)
  {
    Error_Handler();
  }

}

static void MX_DMA_Init(void)
{

  __HAL_RCC_DMA1_CLK_ENABLE();

  HAL_NVIC_SetPriority(DMA1_Channel1_IRQn, 0, 0);
  HAL_NVIC_EnableIRQ(DMA1_Channel1_IRQn);

}

static void MX_GPIO_Init(void)
{
  GPIO_InitTypeDef GPIO_InitStruct = {0};

  __HAL_RCC_GPIOD_CLK_ENABLE();
  __HAL_RCC_GPIOA_CLK_ENABLE();
  __HAL_RCC_GPIOB_CLK_ENABLE();

  HAL_GPIO_WritePin(GPIOA, biprly_Pin|highrly_Pin|lowrly_Pin, GPIO_PIN_RESET);

  HAL_GPIO_WritePin(hv_en_GPIO_Port, hv_en_Pin, GPIO_PIN_RESET);

  GPIO_InitStruct.Pin = biprly_Pin|highrly_Pin|lowrly_Pin;
  GPIO_InitStruct.Mode = GPIO_MODE_OUTPUT_PP;
  GPIO_InitStruct.Pull = GPIO_NOPULL;
  GPIO_InitStruct.Speed = GPIO_SPEED_FREQ_LOW;
  HAL_GPIO_Init(GPIOA, &GPIO_InitStruct);

  GPIO_InitStruct.Pin = GPIO_PIN_7;
  GPIO_InitStruct.Mode = GPIO_MODE_IT_RISING_FALLING;
  GPIO_InitStruct.Pull = GPIO_NOPULL;
  HAL_GPIO_Init(GPIOA, &GPIO_InitStruct);

  GPIO_InitStruct.Pin = GPIO_PIN_0;
  GPIO_InitStruct.Mode = GPIO_MODE_IT_RISING_FALLING;
  GPIO_InitStruct.Pull = GPIO_NOPULL;
  HAL_GPIO_Init(GPIOB, &GPIO_InitStruct);

  GPIO_InitStruct.Pin = hv_en_Pin;
  GPIO_InitStruct.Mode = GPIO_MODE_OUTPUT_PP;
  GPIO_InitStruct.Pull = GPIO_NOPULL;
  GPIO_InitStruct.Speed = GPIO_SPEED_FREQ_LOW;
  HAL_GPIO_Init(hv_en_GPIO_Port, &GPIO_InitStruct);

  HAL_NVIC_SetPriority(EXTI0_IRQn, 0, 0);
  HAL_NVIC_EnableIRQ(EXTI0_IRQn);

  HAL_NVIC_SetPriority(EXTI9_5_IRQn, 0, 0);
  HAL_NVIC_EnableIRQ(EXTI9_5_IRQn);

}

/* USER CODE BEGIN 4 */

static uint8_t var_icon_is_user_key(uint16_t val) {
    return (val >= MIN_VAR_ICON_VALUE && val <= VAR_ICON_KEY_MAX);
}

static void var_icon_user_changed(uint16_t new_value) {
    if (!var_icon_is_user_key(new_value)) {
        return;
    }
    if (new_value == var_icon_value) {
        return;
    }
    dwin_set_var_icon(new_value);
    eeprom_save_var_icon();
    var_icon_user_locked = 1;
}

void send_low_to_display(void) {
    low_sync_both_vps();
}

void save_reading(void) {
    if (number_eeprome_flag) {
        number_eeprome_flag = false;

        // ============== FIX: Handle variable icon at VP 0x2000 ==============
        if (address == VP_VAR_ICON) {
            uint16_t new_value = dataa;

            if (var_icon_from_mode_key(new_value) != 0U) {
                var_icon_apply_return_key(new_value);
                return;
            }
            if (current_page == PAGE_LOW_SET) {
                return;
            }

            if (new_value == var_icon_value) {
                return;
            }

            if (var_icon_is_user_key(new_value)) {
                var_icon_user_changed(new_value);
                return;
            }

            if (var_icon_user_locked) {
                return;
            }

            if (HAL_GetTick() < var_icon_save_enable_tick) {
                return;
            }

            if (new_value < MIN_VAR_ICON_VALUE) {
                return;
            }

            return;
        }

        // ============== FIX: Handle mode at VP 0x3000 ==============
        if (address == VP_MODE) {
            uint16_t new_mode = mode_normalize(dataa);
            if (new_mode == 0U) {
                return;
            }
            if (new_mode == 0x4eU) {
                var_icon_apply_return_key(MODE_KEY_LOW);
            } else {
                vp3003_apply_mode_key(new_mode);
            }
            return;
        }

        if (HAL_GetTick() < boot_rx_lock_until) {
            return;
        }

        // VP 0x1000 increment button — VP 0x3002 is the numeric display
        if (address == VP_LOW_VALUE || address == VP_LOW_DATA) {
#if LOW_DIAG_RAW
            /* TEMP: freeze the display to the RAW DWIN word so we can read it.
             * Setting low_user_touched + last_accept_tick makes dwin_tx_low_quiet
             * true, which stops low_hold_service from repainting over us. */
            if (address == VP_LOW_VALUE) {
                low = dataa;
                previous_low = dataa;
                low_user_touched = 1;
                low_last_accept_tick = HAL_GetTick();
                uint8_t dc[8] = {0x5A, 0xA5, 0x05, 0x82,
                                 (uint8_t)((VP_LOW_DATA >> 8) & 0xFF),
                                 (uint8_t)(VP_LOW_DATA & 0xFF),
                                 (uint8_t)((dataa >> 8) & 0xFF),
                                 (uint8_t)(dataa & 0xFF)};
                dwin_uart_send(dc, 8);
                return;
            }
#endif
            uint16_t rx_tenths = low_rx_to_tenths(dataa);
            if (rx_tenths == low || rx_tenths == low_last_tx_word) {
                if (RxData[3] == 0x82) {
                    return;
                }
            }
            if (address == VP_LOW_VALUE) {
                low_user_touched = 1;
                low_display_push_until = 0;
                var_icon_aggressive_until = 0;
            }
            low_handle_rx(dataa, address);
            return;
        }

        // VP 0x3003 — page 1 high/bipolar value only (low uses VP 0x1000 on page 2)
        if (address == VP_MODE_DATA) {
            if (HAL_GetTick() < boot_rx_lock_until) {
                return;
            }
            if (mode == 0x4f || mode == 0x4d) {
                vp3003_handle_page1_rx(dataa);
            }
            return;
        }

        // VP 0x0082 backlight — save EEPROM, enforce minimum 80
        if (address == VP_BRIGHTNESS || address == 0x82) {
            brightness_handle_rx(dataa);
            return;
        }

        // Handle other addresses
        switch (address) {
        case 0x2001:
            if (dataa == 0x01) {
                if ((mode == 0x4f) || (mode == 0x4d)) {
                    dwin_open_page1();
                } else if (mode == 0x4e) {
                    dwin_open_page2();
                }
            }
            break;
        }
    }
}

void send_loadings(void) {
    if (mode != previous_mode) {
        uint16_t old_mode = previous_mode;
        eeprom_persist_leaving_state(old_mode);
        dwin_set_var_icon(var_icon_from_mode(mode));
        if (mode == 0x4e) {
            dwin_show_settings_page(PAGE_LOW_SET);
        } else if (mode == 0x4f || mode == 0x4d) {
            vp3003_paint_active_fast();
            dwin_show_settings_page(PAGE_HIBI_SET);
        }
        eeprom_save_mode_now();
        previous_mode = mode;
    }
}

void debouncing(void) {
    if (pa7_pending) {
        if ((HAL_GetTick() - pa7_last_irq) >= DEBOUNCE_MS) {
            pa7_pending = 0;
            footswitch = (HAL_GPIO_ReadPin(GPIOA, GPIO_PIN_7) == GPIO_PIN_RESET);
        }
    }
    if (pb0_pending) {
        if ((HAL_GetTick() - pb0_last_irq) >= DEBOUNCE_MS) {
            pb0_pending = 0;
            active = (HAL_GPIO_ReadPin(GPIOB, GPIO_PIN_0) == GPIO_PIN_RESET);
        }
    }
}

void hv_adc_reading(void)
{
    if ((HAL_GetTick() - last_adc_tick) >= 10)
    {
        last_adc_tick = HAL_GetTick();

         adc_raw_ch1 = adc_dma_buf[0];
         adc_raw_ch0 = adc_dma_buf[1];

         ch1_voltage = (adc_raw_ch1 * VDDA_VOLTAGE) / ADC_MAX_VALUE;
         ch0_voltage = (adc_raw_ch0 * VDDA_VOLTAGE) / ADC_MAX_VALUE;

        alert_gate = 0;
        alert_hv = 0;

        if (ch0_voltage > HIGH_THRESHOLD_CH0 || ch0_voltage < LOW_THRESHOLD_CH0)
        {
            alert_gate = 1;
        }
        if (ch1_voltage > HIGH_THRESHOLD_CH1 || ch1_voltage < LOW_THRESHOLD_CH1)
        {
            alert_hv = 1;
        }
    }
}

void bi_hi_pwm(uint16_t dataa) {
    switch (dataa) {
    case 0:  TIM3->CCR1 = 0;    break;
    case 1:  TIM3->CCR1 = 102;  break;
    case 2:  TIM3->CCR1 = 186;  break;
    case 3:  TIM3->CCR1 = 246;  break;
    case 4:  TIM3->CCR1 = 307;  break;
    case 5:  TIM3->CCR1 = 353;  break;
    case 6:  TIM3->CCR1 = 384;  break;
    case 7:  TIM3->CCR1 = 423;  break;
    case 8:  TIM3->CCR1 = 458;  break;
    case 9:  TIM3->CCR1 = 496;  break;
    case 10: TIM3->CCR1 = 524;  break;
    case 11: TIM3->CCR1 = 544;  break;
    case 12: TIM3->CCR1 = 583;  break;
    case 13: TIM3->CCR1 = 609;  break;
    case 14: TIM3->CCR1 = 630;  break;
    case 15: TIM3->CCR1 = 655;  break;
    case 16: TIM3->CCR1 = 673;  break;
    case 17: TIM3->CCR1 = 697;  break;
    case 18: TIM3->CCR1 = 717;  break;
    case 19: TIM3->CCR1 = 742;  break;
    case 20: TIM3->CCR1 = 754;  break;
    case 21: TIM3->CCR1 = 781;  break;
    case 22: TIM3->CCR1 = 803;  break;
    case 23: TIM3->CCR1 = 812;  break;
    case 24: TIM3->CCR1 = 836;  break;
    case 25: TIM3->CCR1 = 856;  break;
    case 26: TIM3->CCR1 = 867;  break;
    case 27: TIM3->CCR1 = 889;  break;
    case 28: TIM3->CCR1 = 901;  break;
    case 29: TIM3->CCR1 = 930;  break;
    case 30: TIM3->CCR1 = 948;  break;
    case 31: TIM3->CCR1 = 960;  break;
    case 32: TIM3->CCR1 = 981;  break;
    case 33: TIM3->CCR1 = 989;  break;
    case 34: TIM3->CCR1 = 998;  break;
    case 35: TIM3->CCR1 = 998;  break;
    default: TIM3->CCR1 = 0;    break;
    }
}

void lowfunction(uint16_t dataa) {
    if (dataa > 200) dataa = 200;

    uint32_t pwm_value = 0;

    switch (dataa) {
        case 0:   pwm_value = 0;    break;   case 1:   pwm_value = 12;   break;
        case 2:   pwm_value = 42;   break;   case 3:   pwm_value = 69;   break;
        case 4:   pwm_value = 98;   break;   case 5:   pwm_value = 114;  break;
        case 6:   pwm_value = 139;  break;   case 7:   pwm_value = 158;  break;
        case 8:   pwm_value = 171;  break;   case 9:   pwm_value = 181;  break;
        case 10:  pwm_value = 196;  break;   case 11:  pwm_value = 207;  break;
        case 12:  pwm_value = 215;  break;   case 13:  pwm_value = 226;  break;
        case 14:  pwm_value = 226;  break;   case 15:  pwm_value = 239;  break;
        case 16:  pwm_value = 249;  break;   case 17:  pwm_value = 262;  break;
        case 18:  pwm_value = 271;  break;   case 19:  pwm_value = 271;  break;
        case 20:  pwm_value = 279;  break;   case 21:  pwm_value = 298;  break;
        case 22:  pwm_value = 298;  break;   case 23:  pwm_value = 309;  break;
        case 24:  pwm_value = 319;  break;   case 25:  pwm_value = 319;  break;
        case 26:  pwm_value = 332;  break;   case 27:  pwm_value = 332;  break;
        case 28:  pwm_value = 341;  break;   case 29:  pwm_value = 341;  break;
        case 30:  pwm_value = 352;  break;   case 31:  pwm_value = 363;  break;
        case 32:  pwm_value = 363;  break;   case 33:  pwm_value = 375;  break;
        case 34:  pwm_value = 375;  break;   case 35:  pwm_value = 385;  break;
        case 36:  pwm_value = 385;  break;   case 37:  pwm_value = 396;  break;
        case 38:  pwm_value = 396;  break;   case 39:  pwm_value = 405;  break;
        case 40:  pwm_value = 408;  break;   case 41:  pwm_value = 419;  break;
        case 42:  pwm_value = 419;  break;   case 43:  pwm_value = 428;  break;
        case 44:  pwm_value = 428;  break;   case 45:  pwm_value = 438;  break;
        case 46:  pwm_value = 438;  break;   case 47:  pwm_value = 438;  break;
        case 48:  pwm_value = 454;  break;   case 49:  pwm_value = 454;  break;
        case 50:  pwm_value = 463;  break;   case 51:  pwm_value = 462;  break;
        case 52:  pwm_value = 475;  break;   case 53:  pwm_value = 475;  break;
        case 54:  pwm_value = 475;  break;   case 55:  pwm_value = 482;  break;
        case 56:  pwm_value = 488;  break;   case 57:  pwm_value = 501;  break;
        case 58:  pwm_value = 501;  break;   case 59:  pwm_value = 501;  break;
        case 60:  pwm_value = 502;  break;   case 61:  pwm_value = 512;  break;
        case 62:  pwm_value = 524;  break;   case 63:  pwm_value = 524;  break;
        case 64:  pwm_value = 524;  break;   case 65:  pwm_value = 537;  break;
        case 66:  pwm_value = 537;  break;   case 67:  pwm_value = 547;  break;
        case 68:  pwm_value = 547;  break;   case 69:  pwm_value = 547;  break;
        case 70:  pwm_value = 557;  break;   case 71:  pwm_value = 557;  break;
        case 72:  pwm_value = 557;  break;   case 73:  pwm_value = 568;  break;
        case 74:  pwm_value = 568;  break;   case 75:  pwm_value = 568;  break;
        case 76:  pwm_value = 577;  break;   case 77:  pwm_value = 577;  break;
        case 78:  pwm_value = 577;  break;   case 79:  pwm_value = 589;  break;
        case 80:  pwm_value = 589;  break;   case 81:  pwm_value = 589;  break;
        case 82:  pwm_value = 598;  break;   case 83:  pwm_value = 598;  break;
        case 84:  pwm_value = 598;  break;   case 85:  pwm_value = 611;  break;
        case 86:  pwm_value = 611;  break;   case 87:  pwm_value = 611;  break;
        case 88:  pwm_value = 621;  break;   case 89:  pwm_value = 621;  break;
        case 90:  pwm_value = 621;  break;   case 91:  pwm_value = 633;  break;
        case 92:  pwm_value = 633;  break;   case 93:  pwm_value = 633;  break;
        case 94:  pwm_value = 647;  break;   case 95:  pwm_value = 647;  break;
        case 96:  pwm_value = 647;  break;   case 97:  pwm_value = 658;  break;
        case 98:  pwm_value = 658;  break;   case 99:  pwm_value = 671;  break;
        case 100: pwm_value = 671; break;    case 101: pwm_value = 682; break;
        case 102: pwm_value = 686; break;    case 103: pwm_value = 690; break;
        case 104: pwm_value = 694; break;    case 105: pwm_value = 698; break;
        case 106: pwm_value = 700; break;    case 107: pwm_value = 701; break;
        case 108: pwm_value = 702; break;    case 109: pwm_value = 702; break;
        case 110: pwm_value = 702; break;    case 111: pwm_value = 705; break;
        case 112: pwm_value = 708; break;    case 113: pwm_value = 710; break;
        case 114: pwm_value = 713; break;    case 115: pwm_value = 716; break;
        case 116: pwm_value = 718; break;    case 117: pwm_value = 721; break;
        case 118: pwm_value = 723; break;    case 119: pwm_value = 724; break;
        case 120: pwm_value = 725; break;    case 121: pwm_value = 730; break;
        case 122: pwm_value = 735; break;    case 123: pwm_value = 740; break;
        case 124: pwm_value = 745; break;    case 125: pwm_value = 748; break;
        case 126: pwm_value = 750; break;    case 127: pwm_value = 753; break;
        case 128: pwm_value = 755; break;    case 129: pwm_value = 756; break;
        case 130: pwm_value = 757; break;    case 131: pwm_value = 762; break;
        case 132: pwm_value = 767; break;    case 133: pwm_value = 772; break;
        case 134: pwm_value = 777; break;    case 135: pwm_value = 782; break;
        case 136: pwm_value = 785; break;    case 137: pwm_value = 787; break;
        case 138: pwm_value = 789; break;    case 139: pwm_value = 790; break;
        case 140: pwm_value = 790; break;    case 141: pwm_value = 795; break;
        case 142: pwm_value = 798; break;    case 143: pwm_value = 801; break;
        case 144: pwm_value = 804; break;    case 145: pwm_value = 807; break;
        case 146: pwm_value = 809; break;    case 147: pwm_value = 811; break;
        case 148: pwm_value = 812; break;    case 149: pwm_value = 813; break;
        case 150: pwm_value = 813; break;    case 151: pwm_value = 818; break;
        case 152: pwm_value = 823; break;    case 153: pwm_value = 828; break;
        case 154: pwm_value = 833; break;    case 155: pwm_value = 838; break;
        case 156: pwm_value = 841; break;    case 157: pwm_value = 844; break;
        case 158: pwm_value = 845; break;    case 159: pwm_value = 846; break;
        case 160: pwm_value = 847; break;    case 161: pwm_value = 852; break;
        case 162: pwm_value = 856; break;    case 163: pwm_value = 860; break;
        case 164: pwm_value = 863; break;    case 165: pwm_value = 866; break;
        case 166: pwm_value = 868; break;    case 167: pwm_value = 869; break;
        case 168: pwm_value = 869; break;    case 169: pwm_value = 869; break;
        case 170: pwm_value = 869; break;    case 171: pwm_value = 874; break;
        case 172: pwm_value = 879; break;    case 173: pwm_value = 884; break;
        case 174: pwm_value = 887; break;    case 175: pwm_value = 890; break;
        case 176: pwm_value = 892; break;    case 177: pwm_value = 893; break;
        case 178: pwm_value = 894; break;    case 179: pwm_value = 895; break;
        case 180: pwm_value = 895; break;    case 181: pwm_value = 900; break;
        case 182: pwm_value = 905; break;    case 183: pwm_value = 910; break;
        case 184: pwm_value = 915; break;    case 185: pwm_value = 918; break;
        case 186: pwm_value = 920; break;    case 187: pwm_value = 923; break;
        case 188: pwm_value = 926; break;    case 189: pwm_value = 928; break;
        case 190: pwm_value = 930; break;    case 191: pwm_value = 934; break;
        case 192: pwm_value = 938; break;    case 193: pwm_value = 941; break;
        case 194: pwm_value = 944; break;    case 195: pwm_value = 947; break;
        case 196: pwm_value = 949; break;    case 197: pwm_value = 950; break;
        case 198: pwm_value = 951; break;    case 199: pwm_value = 952; break;
        case 200: pwm_value = 952; break;
        default: pwm_value = 0; break;
    }

    TIM3->CCR1 = pwm_value;
}
/* USER CODE END 4 */

void Error_Handler(void)
{
    __disable_irq();
    while (1) {
    }
}
